AUTOSAR XML (schema 00048)
package /AUTOLIV/SoftwareComponents/CIL
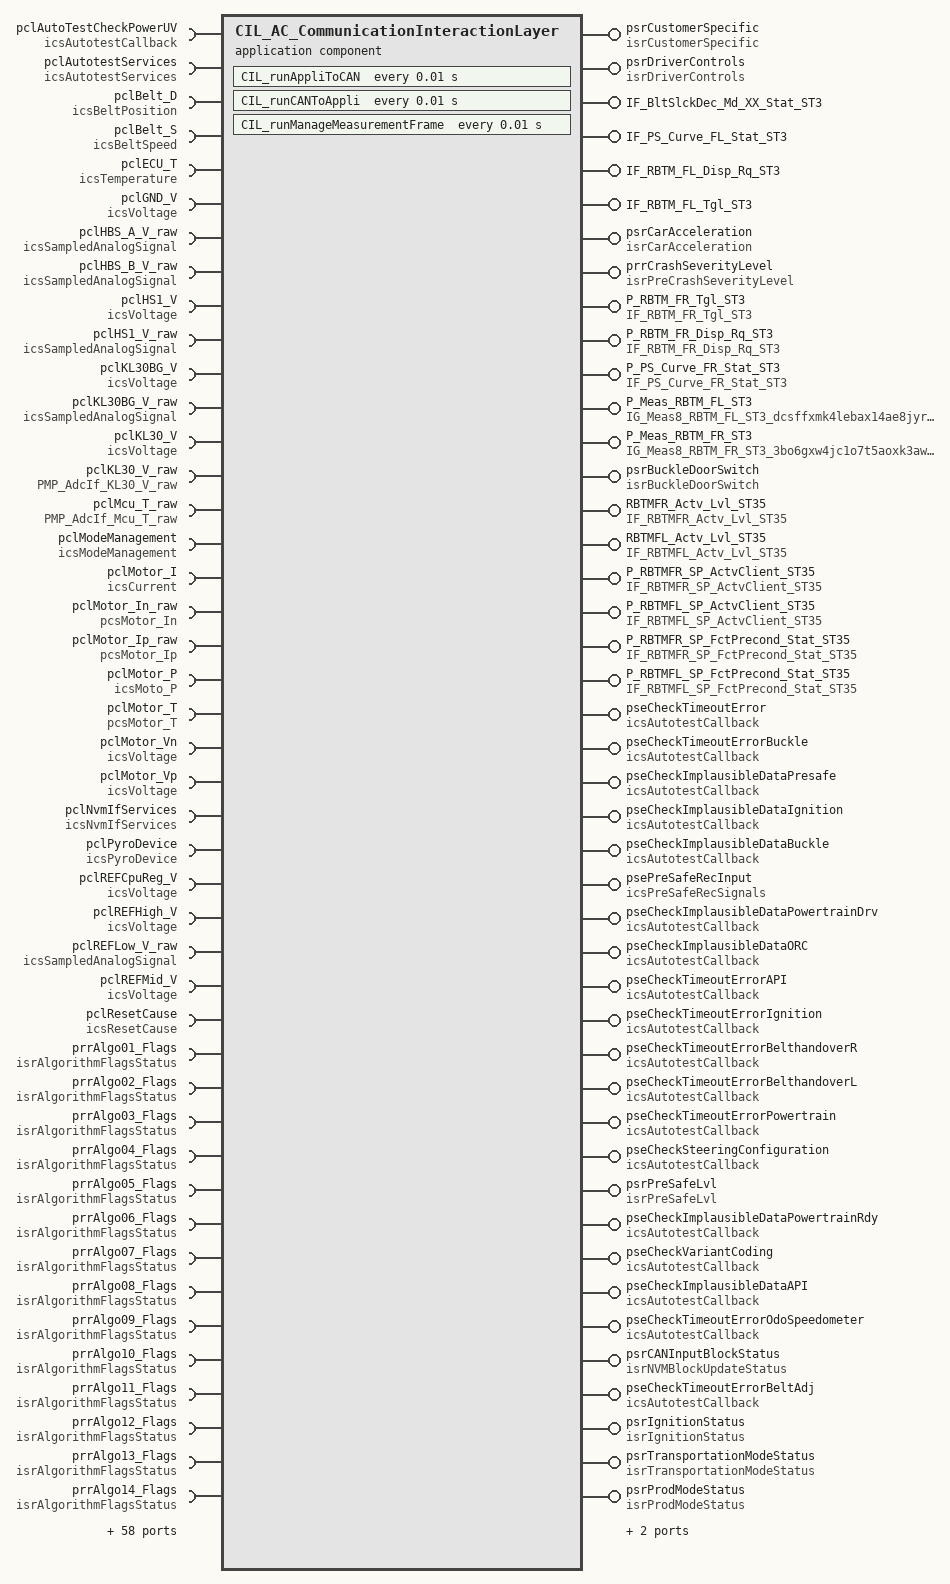
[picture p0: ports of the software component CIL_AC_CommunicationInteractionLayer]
  application sw component type CIL_AC_CommunicationInteractionLayer
    69 x require port:
      pclAutoTestCheckPowerUV: client-com-spec=AutotestCallback, required-interface=icsAutotestCallback
      pclAutotestServices: required-com-specs=[GetLastCriticalAutotestID, GetTestResult], required-interface=icsAutotestServices
      pclBelt_D: required-com-specs=[GetFromMinPos_deg, GetFromMinPos_mm, GetFromT0_deg, GetFromT0_mm, GetRange_deg, GetRange_mm], required-interface=icsBeltPosition
      pclBelt_S: required-com-specs=[GetSpeed_SingleEdge_deg_s, GetSpeed_deg_s, GetSpeed_mm_s], required-interface=icsBeltSpeed
      pclECU_T: required-com-specs=[GetFiltered, GetFiltered_deg, Init], required-interface=icsTemperature
      pclGND_V: required-com-specs=[Get, Get_100ms, Get_10ms, Get_20ms, Get_2ms], required-interface=icsVoltage
      pclHBS_A_V_raw: required-com-specs=[Get, Get_100ms, Get_10ms, Get_20ms, Get_2ms], required-interface=icsSampledAnalogSignal
      pclHBS_B_V_raw: required-com-specs=[Get, Get_100ms, Get_10ms, Get_20ms, Get_2ms], required-interface=icsSampledAnalogSignal
      pclHS1_V: required-com-specs=[Get, Get_100ms, Get_10ms, Get_20ms, Get_2ms], required-interface=icsVoltage
      pclHS1_V_raw: required-com-specs=[Get, Get_100ms, Get_10ms, Get_20ms, Get_2ms], required-interface=icsSampledAnalogSignal
      pclKL30BG_V: required-com-specs=[Get, Get_100ms, Get_10ms, Get_20ms, Get_2ms], required-interface=icsVoltage
      pclKL30BG_V_raw: required-com-specs=[Get, Get_100ms, Get_10ms, Get_20ms, Get_2ms], required-interface=icsSampledAnalogSignal
      pclKL30_V: required-com-specs=[Get, Get_100ms, Get_10ms, Get_20ms, Get_2ms], required-interface=icsVoltage
      pclKL30_V_raw: required-com-specs=[Get_10ms, Get_100ms, Get, Get_20ms, Get_2ms], required-interface=PMP_AdcIf_KL30_V_raw
      pclMcu_T_raw: client-com-spec=Get_10ms, required-interface=PMP_AdcIf_Mcu_T_raw
      pclModeManagement: client-com-spec=CheckModeStatus, required-interface=icsModeManagement
      pclMotor_I: required-com-specs=[ConvertCurrent_mAtoLSB, Get_A, Get_LSB, Get_mA], required-interface=icsCurrent
      pclMotor_In_raw: required-com-specs=[raw_Get_10ms, raw_Get], required-interface=pcsMotor_In
      pclMotor_Ip_raw: required-com-specs=[raw_Get_10ms, raw_Get], required-interface=pcsMotor_Ip
      pclMotor_P: required-com-specs=[GetPowerOrder, SetPowerOrder], required-interface=icsMoto_P
      pclMotor_T: required-com-specs=[GetDeficiencyLevel, InitializeDeficiencyLevel], required-interface=pcsMotor_T
      pclMotor_Vn: required-com-specs=[Get, Get_100ms, Get_10ms, Get_20ms, Get_2ms], required-interface=icsVoltage
      pclMotor_Vp: required-com-specs=[Get, Get_100ms, Get_10ms, Get_20ms, Get_2ms], required-interface=icsVoltage
      pclNvmIfServices: required-com-specs=[GetCalibBlockLength, GetNvmBlockLength, GetNvmBlockStatus, SynchronousRecord], required-interface=icsNvmIfServices
      pclPyroDevice: client-com-spec=GetPyroActivationStatus, required-interface=icsPyroDevice
      pclREFCpuReg_V: required-com-specs=[Get, Get_100ms, Get_10ms, Get_20ms, Get_2ms], required-interface=icsVoltage
      pclREFHigh_V: required-com-specs=[Get, Get_100ms, Get_10ms, Get_20ms, Get_2ms], required-interface=icsVoltage
      pclREFLow_V_raw: required-com-specs=[Get, Get_100ms, Get_10ms, Get_20ms, Get_2ms], required-interface=icsSampledAnalogSignal
      pclREFMid_V: required-com-specs=[Get, Get_100ms, Get_10ms, Get_20ms, Get_2ms], required-interface=icsVoltage
      pclResetCause: required-com-specs=[ConfirmResetCause, DetermineResetCause, GetResetCause], required-interface=icsResetCause
      prrAlgo01_Flags: required-interface=isrAlgorithmFlagsStatus
        required-com-specs:
          data-element=b8InterruptFlag, init-value=constant-reference=APPLINIT_KB8_ALGO_FLAG_FALSE
          data-element=b8PreActivationFlag, init-value=constant-reference=APPLINIT_KB8_ALGO_FLAG_FALSE
          data-element=b8PreConditionsFlag, init-value=constant-reference=APPLINIT_KB8_ALGO_FLAG_FALSE
          data-element=b8TriggerFlag, init-value=constant-reference=APPLINIT_KB8_ALGO_FLAG_FALSE
          data-element=u8TriggeringSource, init-value=constant-reference=APPLINIT_KU8_TRIGGERING_SOURCE_NO
      prrAlgo02_Flags: required-interface=isrAlgorithmFlagsStatus
        required-com-specs:
          data-element=b8InterruptFlag, init-value=constant-reference=APPLINIT_KB8_ALGO_FLAG_FALSE
          data-element=b8PreActivationFlag, init-value=constant-reference=APPLINIT_KB8_ALGO_FLAG_FALSE
          data-element=b8PreConditionsFlag, init-value=constant-reference=APPLINIT_KB8_ALGO_FLAG_FALSE
          data-element=b8TriggerFlag, init-value=constant-reference=APPLINIT_KB8_ALGO_FLAG_FALSE
          data-element=u8TriggeringSource, init-value=constant-reference=APPLINIT_KU8_TRIGGERING_SOURCE_NO
      prrAlgo03_Flags: required-interface=isrAlgorithmFlagsStatus
        required-com-specs:
          data-element=b8InterruptFlag, init-value=constant-reference=APPLINIT_KB8_ALGO_FLAG_FALSE
          data-element=b8PreActivationFlag, init-value=constant-reference=APPLINIT_KB8_ALGO_FLAG_FALSE
          data-element=b8PreConditionsFlag, init-value=constant-reference=APPLINIT_KB8_ALGO_FLAG_FALSE
          data-element=b8TriggerFlag, init-value=constant-reference=APPLINIT_KB8_ALGO_FLAG_FALSE
          data-element=u8TriggeringSource, init-value=constant-reference=APPLINIT_KU8_TRIGGERING_SOURCE_NO
      prrAlgo04_Flags: required-interface=isrAlgorithmFlagsStatus
        required-com-specs:
          data-element=b8InterruptFlag, init-value=constant-reference=APPLINIT_KB8_ALGO_FLAG_FALSE
          data-element=b8PreActivationFlag, init-value=constant-reference=APPLINIT_KB8_ALGO_FLAG_FALSE
          data-element=b8PreConditionsFlag, init-value=constant-reference=APPLINIT_KB8_ALGO_FLAG_FALSE
          data-element=b8TriggerFlag, init-value=constant-reference=APPLINIT_KB8_ALGO_FLAG_FALSE
          data-element=u8TriggeringSource, init-value=constant-reference=APPLINIT_KU8_TRIGGERING_SOURCE_NO
      prrAlgo05_Flags: required-interface=isrAlgorithmFlagsStatus
        required-com-specs:
          data-element=b8InterruptFlag, init-value=constant-reference=APPLINIT_KB8_ALGO_FLAG_FALSE
          data-element=b8PreActivationFlag, init-value=constant-reference=APPLINIT_KB8_ALGO_FLAG_FALSE
          data-element=b8PreConditionsFlag, init-value=constant-reference=APPLINIT_KB8_ALGO_FLAG_FALSE
          data-element=b8TriggerFlag, init-value=constant-reference=APPLINIT_KB8_ALGO_FLAG_FALSE
          data-element=u8TriggeringSource, init-value=constant-reference=APPLINIT_KU8_TRIGGERING_SOURCE_NO
      prrAlgo06_Flags: required-interface=isrAlgorithmFlagsStatus
        required-com-specs:
          data-element=b8InterruptFlag, init-value=constant-reference=APPLINIT_KB8_ALGO_FLAG_FALSE
          data-element=b8PreActivationFlag, init-value=constant-reference=APPLINIT_KB8_ALGO_FLAG_FALSE
          data-element=b8PreConditionsFlag, init-value=constant-reference=APPLINIT_KB8_ALGO_FLAG_FALSE
          data-element=b8TriggerFlag, init-value=constant-reference=APPLINIT_KB8_ALGO_FLAG_FALSE
          data-element=u8TriggeringSource, init-value=constant-reference=APPLINIT_KU8_TRIGGERING_SOURCE_NO
      prrAlgo07_Flags: required-interface=isrAlgorithmFlagsStatus
        required-com-specs:
          data-element=b8InterruptFlag, init-value=constant-reference=APPLINIT_KB8_ALGO_FLAG_FALSE
          data-element=b8PreActivationFlag, init-value=constant-reference=APPLINIT_KB8_ALGO_FLAG_FALSE
          data-element=b8PreConditionsFlag, init-value=constant-reference=APPLINIT_KB8_ALGO_FLAG_FALSE
          data-element=b8TriggerFlag, init-value=constant-reference=APPLINIT_KB8_ALGO_FLAG_FALSE
          data-element=u8TriggeringSource, init-value=constant-reference=APPLINIT_KU8_TRIGGERING_SOURCE_NO
      prrAlgo08_Flags: required-interface=isrAlgorithmFlagsStatus
        required-com-specs:
          data-element=b8InterruptFlag, init-value=constant-reference=APPLINIT_KB8_ALGO_FLAG_FALSE
          data-element=b8PreActivationFlag, init-value=constant-reference=APPLINIT_KB8_ALGO_FLAG_FALSE
          data-element=b8PreConditionsFlag, init-value=constant-reference=APPLINIT_KB8_ALGO_FLAG_FALSE
          data-element=b8TriggerFlag, init-value=constant-reference=APPLINIT_KB8_ALGO_FLAG_FALSE
          data-element=u8TriggeringSource, init-value=constant-reference=APPLINIT_KU8_TRIGGERING_SOURCE_NO
      prrAlgo09_Flags: required-interface=isrAlgorithmFlagsStatus
        required-com-specs:
          data-element=b8InterruptFlag, init-value=constant-reference=APPLINIT_KB8_ALGO_FLAG_FALSE
          data-element=b8PreActivationFlag, init-value=constant-reference=APPLINIT_KB8_ALGO_FLAG_FALSE
          data-element=b8PreConditionsFlag, init-value=constant-reference=APPLINIT_KB8_ALGO_FLAG_FALSE
          data-element=b8TriggerFlag, init-value=constant-reference=APPLINIT_KB8_ALGO_FLAG_FALSE
          data-element=u8TriggeringSource, init-value=constant-reference=APPLINIT_KU8_TRIGGERING_SOURCE_NO
      prrAlgo10_Flags: required-interface=isrAlgorithmFlagsStatus
        required-com-specs:
          data-element=b8InterruptFlag, init-value=constant-reference=APPLINIT_KB8_ALGO_FLAG_FALSE
          data-element=b8PreActivationFlag, init-value=constant-reference=APPLINIT_KB8_ALGO_FLAG_FALSE
          data-element=b8PreConditionsFlag, init-value=constant-reference=APPLINIT_KB8_ALGO_FLAG_FALSE
          data-element=b8TriggerFlag, init-value=constant-reference=APPLINIT_KB8_ALGO_FLAG_FALSE
          data-element=u8TriggeringSource, init-value=constant-reference=APPLINIT_KU8_TRIGGERING_SOURCE_NO
      prrAlgo11_Flags: required-interface=isrAlgorithmFlagsStatus
        required-com-specs:
          data-element=b8InterruptFlag, init-value=constant-reference=APPLINIT_KB8_ALGO_FLAG_FALSE
          data-element=b8PreActivationFlag, init-value=constant-reference=APPLINIT_KB8_ALGO_FLAG_FALSE
          data-element=b8PreConditionsFlag, init-value=constant-reference=APPLINIT_KB8_ALGO_FLAG_FALSE
          data-element=b8TriggerFlag, init-value=constant-reference=APPLINIT_KB8_ALGO_FLAG_FALSE
          data-element=u8TriggeringSource, init-value=constant-reference=APPLINIT_KU8_TRIGGERING_SOURCE_NO
      prrAlgo12_Flags: required-interface=isrAlgorithmFlagsStatus
        required-com-specs:
          data-element=b8InterruptFlag, init-value=constant-reference=APPLINIT_KB8_ALGO_FLAG_FALSE
          data-element=b8PreActivationFlag, init-value=constant-reference=APPLINIT_KB8_ALGO_FLAG_FALSE
          data-element=b8PreConditionsFlag, init-value=constant-reference=APPLINIT_KB8_ALGO_FLAG_FALSE
          data-element=b8TriggerFlag, init-value=constant-reference=APPLINIT_KB8_ALGO_FLAG_FALSE
          data-element=u8TriggeringSource, init-value=constant-reference=APPLINIT_KU8_TRIGGERING_SOURCE_NO
      prrAlgo13_Flags: required-interface=isrAlgorithmFlagsStatus
        required-com-specs:
          data-element=b8InterruptFlag, init-value=constant-reference=APPLINIT_KB8_ALGO_FLAG_FALSE
          data-element=b8PreActivationFlag, init-value=constant-reference=APPLINIT_KB8_ALGO_FLAG_FALSE
          data-element=b8PreConditionsFlag, init-value=constant-reference=APPLINIT_KB8_ALGO_FLAG_FALSE
          data-element=b8TriggerFlag, init-value=constant-reference=APPLINIT_KB8_ALGO_FLAG_FALSE
          data-element=u8TriggeringSource, init-value=constant-reference=APPLINIT_KU8_TRIGGERING_SOURCE_NO
      prrAlgo14_Flags: required-interface=isrAlgorithmFlagsStatus
        required-com-specs:
          data-element=b8InterruptFlag, init-value=constant-reference=APPLINIT_KB8_ALGO_FLAG_FALSE
          data-element=b8PreActivationFlag, init-value=constant-reference=APPLINIT_KB8_ALGO_FLAG_FALSE
          data-element=b8PreConditionsFlag, init-value=constant-reference=APPLINIT_KB8_ALGO_FLAG_FALSE
          data-element=b8TriggerFlag, init-value=constant-reference=APPLINIT_KB8_ALGO_FLAG_FALSE
          data-element=u8TriggeringSource, init-value=constant-reference=APPLINIT_KU8_TRIGGERING_SOURCE_NO
      prrAlgo15_Flags: required-interface=isrAlgorithmFlagsStatus
        required-com-specs:
          data-element=b8InterruptFlag, init-value=constant-reference=APPLINIT_KB8_ALGO_FLAG_FALSE
          data-element=b8PreActivationFlag, init-value=constant-reference=APPLINIT_KB8_ALGO_FLAG_FALSE
          data-element=b8PreConditionsFlag, init-value=constant-reference=APPLINIT_KB8_ALGO_FLAG_FALSE
          data-element=b8TriggerFlag, init-value=constant-reference=APPLINIT_KB8_ALGO_FLAG_FALSE
          data-element=u8TriggeringSource, init-value=constant-reference=APPLINIT_KU8_TRIGGERING_SOURCE_NO
      prrAlgo16_Flags: required-interface=isrAlgorithmFlagsStatus
        required-com-specs:
          data-element=b8InterruptFlag, init-value=constant-reference=APPLINIT_KB8_ALGO_FLAG_FALSE
          data-element=b8PreActivationFlag, init-value=constant-reference=APPLINIT_KB8_ALGO_FLAG_FALSE
          data-element=b8PreConditionsFlag, init-value=constant-reference=APPLINIT_KB8_ALGO_FLAG_FALSE
          data-element=b8TriggerFlag, init-value=constant-reference=APPLINIT_KB8_ALGO_FLAG_FALSE
          data-element=u8TriggeringSource, init-value=constant-reference=APPLINIT_KU8_TRIGGERING_SOURCE_NO
      prrAlgo17_Flags: required-interface=isrAlgorithmFlagsStatus
        required-com-specs:
          data-element=b8InterruptFlag, init-value=constant-reference=APPLINIT_KB8_ALGO_FLAG_FALSE
          data-element=b8PreActivationFlag, init-value=constant-reference=APPLINIT_KB8_ALGO_FLAG_FALSE
          data-element=b8PreConditionsFlag, init-value=constant-reference=APPLINIT_KB8_ALGO_FLAG_FALSE
          data-element=b8TriggerFlag, init-value=constant-reference=APPLINIT_KB8_ALGO_FLAG_FALSE
          data-element=u8TriggeringSource, init-value=constant-reference=APPLINIT_KU8_TRIGGERING_SOURCE_NO
      prrAlgo18_Flags: required-interface=isrAlgorithmFlagsStatus
        required-com-specs:
          data-element=b8InterruptFlag, init-value=constant-reference=APPLINIT_KB8_ALGO_FLAG_FALSE
          data-element=b8PreActivationFlag, init-value=constant-reference=APPLINIT_KB8_ALGO_FLAG_FALSE
          data-element=b8PreConditionsFlag, init-value=constant-reference=APPLINIT_KB8_ALGO_FLAG_FALSE
          data-element=b8TriggerFlag, init-value=constant-reference=APPLINIT_KB8_ALGO_FLAG_FALSE
          data-element=u8TriggeringSource, init-value=constant-reference=APPLINIT_KU8_TRIGGERING_SOURCE_NO
      prrAlgo19_Flags: required-interface=isrAlgorithmFlagsStatus
        required-com-specs:
          data-element=b8InterruptFlag, init-value=constant-reference=APPLINIT_KB8_ALGO_FLAG_FALSE
          data-element=b8PreActivationFlag, init-value=constant-reference=APPLINIT_KB8_ALGO_FLAG_FALSE
          data-element=b8PreConditionsFlag, init-value=constant-reference=APPLINIT_KB8_ALGO_FLAG_FALSE
          data-element=b8TriggerFlag, init-value=constant-reference=APPLINIT_KB8_ALGO_FLAG_FALSE
          data-element=u8TriggeringSource, init-value=constant-reference=APPLINIT_KU8_TRIGGERING_SOURCE_NO
      prrAlgo20_Flags: required-interface=isrAlgorithmFlagsStatus
        required-com-specs:
          data-element=b8InterruptFlag, init-value=constant-reference=APPLINIT_KB8_ALGO_FLAG_FALSE
          data-element=b8PreActivationFlag, init-value=constant-reference=APPLINIT_KB8_ALGO_FLAG_FALSE
          data-element=b8PreConditionsFlag, init-value=constant-reference=APPLINIT_KB8_ALGO_FLAG_FALSE
          data-element=b8TriggerFlag, init-value=constant-reference=APPLINIT_KB8_ALGO_FLAG_FALSE
          data-element=u8TriggeringSource, init-value=constant-reference=APPLINIT_KU8_TRIGGERING_SOURCE_NO
      prrAlgo21_Flags: required-interface=isrAlgorithmFlagsStatus
        required-com-specs:
          data-element=b8InterruptFlag, init-value=constant-reference=APPLINIT_KB8_ALGO_FLAG_FALSE
          data-element=b8PreActivationFlag, init-value=constant-reference=APPLINIT_KB8_ALGO_FLAG_FALSE
          data-element=b8PreConditionsFlag, init-value=constant-reference=APPLINIT_KB8_ALGO_FLAG_FALSE
          data-element=b8TriggerFlag, init-value=constant-reference=APPLINIT_KB8_ALGO_FLAG_FALSE
          data-element=u8TriggeringSource, init-value=constant-reference=APPLINIT_KU8_TRIGGERING_SOURCE_NO
      prrAlgo22_Flags: required-interface=isrAlgorithmFlagsStatus
        required-com-specs:
          data-element=b8InterruptFlag, init-value=constant-reference=APPLINIT_KB8_ALGO_FLAG_FALSE
          data-element=b8PreActivationFlag, init-value=constant-reference=APPLINIT_KB8_ALGO_FLAG_FALSE
          data-element=b8PreConditionsFlag, init-value=constant-reference=APPLINIT_KB8_ALGO_FLAG_FALSE
          data-element=b8TriggerFlag, init-value=constant-reference=APPLINIT_KB8_ALGO_FLAG_FALSE
          data-element=u8TriggeringSource, init-value=constant-reference=APPLINIT_KU8_TRIGGERING_SOURCE_NO
      prrAlgo23_Flags: required-interface=isrAlgorithmFlagsStatus
        required-com-specs:
          data-element=b8InterruptFlag, init-value=constant-reference=APPLINIT_KB8_ALGO_FLAG_FALSE
          data-element=b8PreActivationFlag, init-value=constant-reference=APPLINIT_KB8_ALGO_FLAG_FALSE
          data-element=b8PreConditionsFlag, init-value=constant-reference=APPLINIT_KB8_ALGO_FLAG_FALSE
          data-element=b8TriggerFlag, init-value=constant-reference=APPLINIT_KB8_ALGO_FLAG_FALSE
          data-element=u8TriggeringSource, init-value=constant-reference=APPLINIT_KU8_TRIGGERING_SOURCE_NO
      prrAlgo24_Flags: required-interface=isrAlgorithmFlagsStatus
        required-com-specs:
          data-element=b8InterruptFlag, init-value=constant-reference=APPLINIT_KB8_ALGO_FLAG_FALSE
          data-element=b8PreActivationFlag, init-value=constant-reference=APPLINIT_KB8_ALGO_FLAG_FALSE
          data-element=b8PreConditionsFlag, init-value=constant-reference=APPLINIT_KB8_ALGO_FLAG_FALSE
          data-element=b8TriggerFlag, init-value=constant-reference=APPLINIT_KB8_ALGO_FLAG_FALSE
          data-element=u8TriggeringSource, init-value=constant-reference=APPLINIT_KU8_TRIGGERING_SOURCE_NO
      prrAlgo25_Flags: required-interface=isrAlgorithmFlagsStatus
        required-com-specs:
          data-element=b8InterruptFlag, init-value=constant-reference=APPLINIT_KB8_ALGO_FLAG_FALSE
          data-element=b8PreActivationFlag, init-value=constant-reference=APPLINIT_KB8_ALGO_FLAG_FALSE
          data-element=b8PreConditionsFlag, init-value=constant-reference=APPLINIT_KB8_ALGO_FLAG_FALSE
          data-element=b8TriggerFlag, init-value=constant-reference=APPLINIT_KB8_ALGO_FLAG_FALSE
          data-element=u8TriggeringSource, init-value=constant-reference=APPLINIT_KU8_TRIGGERING_SOURCE_NO
      prrAlgo26_Flags: required-interface=isrAlgorithmFlagsStatus
        required-com-specs:
          data-element=b8InterruptFlag, init-value=constant-reference=APPLINIT_KB8_ALGO_FLAG_FALSE
          data-element=b8PreActivationFlag, init-value=constant-reference=APPLINIT_KB8_ALGO_FLAG_FALSE
          data-element=b8PreConditionsFlag, init-value=constant-reference=APPLINIT_KB8_ALGO_FLAG_FALSE
          data-element=b8TriggerFlag, init-value=constant-reference=APPLINIT_KB8_ALGO_FLAG_FALSE
          data-element=u8TriggeringSource, init-value=constant-reference=APPLINIT_KU8_TRIGGERING_SOURCE_NO
      prrAlgo30_Flags: required-interface=isrAlgorithmFlagsStatus
        required-com-specs:
          data-element=b8InterruptFlag, init-value=constant-reference=APPLINIT_KB8_ALGO_FLAG_FALSE
          data-element=b8PreActivationFlag, init-value=constant-reference=APPLINIT_KB8_ALGO_FLAG_FALSE
          data-element=b8PreConditionsFlag, init-value=constant-reference=APPLINIT_KB8_ALGO_FLAG_FALSE
          data-element=b8TriggerFlag, init-value=constant-reference=APPLINIT_KB8_ALGO_FLAG_FALSE
          data-element=u8TriggeringSource, init-value=constant-reference=APPLINIT_KU8_TRIGGERING_SOURCE_NO
      prrAlgo31_Flags: required-interface=isrAlgorithmFlagsStatus
        required-com-specs:
          data-element=b8InterruptFlag, init-value=constant-reference=APPLINIT_KB8_ALGO_FLAG_FALSE
          data-element=b8PreActivationFlag, init-value=constant-reference=APPLINIT_KB8_ALGO_FLAG_FALSE
          data-element=b8PreConditionsFlag, init-value=constant-reference=APPLINIT_KB8_ALGO_FLAG_FALSE
          data-element=b8TriggerFlag, init-value=constant-reference=APPLINIT_KB8_ALGO_FLAG_FALSE
          data-element=u8TriggeringSource, init-value=constant-reference=APPLINIT_KU8_TRIGGERING_SOURCE_NO
      prrAlgo32_Flags: required-interface=isrAlgorithmFlagsStatus
        required-com-specs:
          data-element=b8InterruptFlag, init-value=constant-reference=APPLINIT_KB8_ALGO_FLAG_FALSE
          data-element=b8PreActivationFlag, init-value=constant-reference=APPLINIT_KB8_ALGO_FLAG_FALSE
          data-element=b8PreConditionsFlag, init-value=constant-reference=APPLINIT_KB8_ALGO_FLAG_FALSE
          data-element=b8TriggerFlag, init-value=constant-reference=APPLINIT_KB8_ALGO_FLAG_FALSE
          data-element=u8TriggeringSource, init-value=constant-reference=APPLINIT_KU8_TRIGGERING_SOURCE_NO
      prrAlgo33_Flags: required-interface=isrAlgorithmFlagsStatus
        required-com-specs:
          data-element=b8InterruptFlag, init-value=constant-reference=APPLINIT_KB8_ALGO_FLAG_FALSE
          data-element=b8PreActivationFlag, init-value=constant-reference=APPLINIT_KB8_ALGO_FLAG_FALSE
          data-element=b8PreConditionsFlag, init-value=constant-reference=APPLINIT_KB8_ALGO_FLAG_FALSE
          data-element=b8TriggerFlag, init-value=constant-reference=APPLINIT_KB8_ALGO_FLAG_FALSE
          data-element=u8TriggeringSource, init-value=constant-reference=APPLINIT_KU8_TRIGGERING_SOURCE_NO
      prrAlgo34_Flags: required-interface=isrAlgorithmFlagsStatus
        required-com-specs:
          data-element=b8InterruptFlag, init-value=constant-reference=APPLINIT_KB8_ALGO_FLAG_FALSE
          data-element=b8PreActivationFlag, init-value=constant-reference=APPLINIT_KB8_ALGO_FLAG_FALSE
          data-element=b8PreConditionsFlag, init-value=constant-reference=APPLINIT_KB8_ALGO_FLAG_FALSE
          data-element=b8TriggerFlag, init-value=constant-reference=APPLINIT_KB8_ALGO_FLAG_FALSE
          data-element=u8TriggeringSource, init-value=constant-reference=APPLINIT_KU8_TRIGGERING_SOURCE_NO
      prrAlgo35_Flags: required-interface=isrAlgorithmFlagsStatus
        required-com-specs:
          data-element=b8InterruptFlag, init-value=constant-reference=APPLINIT_KB8_ALGO_FLAG_FALSE
          data-element=b8PreActivationFlag, init-value=constant-reference=APPLINIT_KB8_ALGO_FLAG_FALSE
          data-element=b8PreConditionsFlag, init-value=constant-reference=APPLINIT_KB8_ALGO_FLAG_FALSE
          data-element=b8TriggerFlag, init-value=constant-reference=APPLINIT_KB8_ALGO_FLAG_FALSE
          data-element=u8TriggeringSource, init-value=constant-reference=APPLINIT_KU8_TRIGGERING_SOURCE_NO
      prrAlgo36_Flags: required-interface=isrAlgorithmFlagsStatus
        required-com-specs:
          data-element=b8InterruptFlag, init-value=constant-reference=APPLINIT_KB8_ALGO_FLAG_FALSE
          data-element=b8PreActivationFlag, init-value=constant-reference=APPLINIT_KB8_ALGO_FLAG_FALSE
          data-element=b8PreConditionsFlag, init-value=constant-reference=APPLINIT_KB8_ALGO_FLAG_FALSE
          data-element=b8TriggerFlag, init-value=constant-reference=APPLINIT_KB8_ALGO_FLAG_FALSE
          data-element=u8TriggeringSource, init-value=constant-reference=APPLINIT_KU8_TRIGGERING_SOURCE_NO
      prrAlgo37_Flags: required-interface=isrAlgorithmFlagsStatus
        required-com-specs:
          data-element=b8InterruptFlag, init-value=constant-reference=APPLINIT_KB8_ALGO_FLAG_FALSE
          data-element=b8PreActivationFlag, init-value=constant-reference=APPLINIT_KB8_ALGO_FLAG_FALSE
          data-element=b8PreConditionsFlag, init-value=constant-reference=APPLINIT_KB8_ALGO_FLAG_FALSE
          data-element=b8TriggerFlag, init-value=constant-reference=APPLINIT_KB8_ALGO_FLAG_FALSE
          data-element=u8TriggeringSource, init-value=constant-reference=APPLINIT_KU8_TRIGGERING_SOURCE_NO
      prrAlgo38_Flags: required-interface=isrAlgorithmFlagsStatus
        required-com-specs:
          data-element=b8InterruptFlag, init-value=constant-reference=APPLINIT_KB8_ALGO_FLAG_FALSE
          data-element=b8PreActivationFlag, init-value=constant-reference=APPLINIT_KB8_ALGO_FLAG_FALSE
          data-element=b8PreConditionsFlag, init-value=constant-reference=APPLINIT_KB8_ALGO_FLAG_FALSE
          data-element=b8TriggerFlag, init-value=constant-reference=APPLINIT_KB8_ALGO_FLAG_FALSE
          data-element=u8TriggeringSource, init-value=constant-reference=APPLINIT_KU8_TRIGGERING_SOURCE_NO
      prrBeltStackAntipatina: nonqueued-receiver-com-spec{data-element=b8BeltStack, init-value=0}, required-interface=isrBeltStack
      prrCycleNumber: nonqueued-receiver-com-spec{data-element=u8CycleNumber, init-value=constant-reference=APPLINIT_KU8_CYCLE_NUMBER_NONE}, required-interface=isrCycleNumber
      prrSelectedCycle: nonqueued-receiver-com-spec{data-element=u8CycleNumber, init-value=constant-reference=APPLINIT_KU8_CYCLE_NUMBER_NONE}, required-interface=isrCycleNumber
      prrStepNumber: nonqueued-receiver-com-spec{data-element=u8StepNumber, init-value=constant-reference=APPLINIT_KU8_STEP_NUMBER_NONE}, required-interface=isrStepNumber
    6 x provide port:
      psrCustomerSpecific: provided-interface=isrCustomerSpecific
        provided-com-specs:
          data-element=b8HardReleaseRequest, init-value=constant-reference=APPLINIT_KB8_BOOLEAN_FALSE
          data-element=b8IsCarCrankingActive, init-value=constant-reference=APPLINIT_KB8_CAR_CRANKING_ACTIVE_TRUE
          data-element=b8IsCarCrashDetected, init-value=constant-reference=APPLINIT_KB8_CAR_CRASH_DETECTED_FALSE
          data-element=b8IsTrigOffEventAllowed, init-value=constant-reference=APPLINIT_KB8_BOOLEAN_FALSE
          data-element=b8PreCrashRequestEnable, init-value=constant-reference=APPLINIT_KB8_BOOLEAN_FALSE
          data-element=u8BeltSlackStatus, init-value=constant-reference=APPLINIT_KU8_BELT_SLACK_STATUS_NOT_DEFINED
          data-element=u8HapticRequest, init-value=constant-reference=APPLINIT_KU8_HAPTIC_REQUEST_NO
          data-element=u8PreCrashRequest, init-value=constant-reference=APPLINIT_KU8_PRE_CRASH_REQUEST_NO_REQUEST
          data-element=u8TriggerRequest, init-value=constant-reference=APPLINIT_KU8_CYCLE_NUMBER_NONE
          data-element=b8SignalRelInhibition, init-value=constant-reference=APPLINIT_KB8_BOOLEAN_FALSE
      psrDriverControls: provided-interface=isrDriverControls
        provided-com-specs:
          data-element=b8VehicleMovingBackwards, init-value=constant-reference=APPLINIT_KB8_BOOLEAN_FALSE
          data-element=s16AccelerationPedalPositionRate, init-value=constant-reference=APPLINIT_KS16_ACCEL_PEDAL_POS_RATE_ZERO
          data-element=s16BrakePressureRate, init-value=constant-reference=APPLINIT_KS16_BRAKE_PRESSURE_RATE_ZERO
          data-element=s16HWAngle, init-value=constant-reference=APPLINIT_KS16_HW_ANGLE_ZERO
          data-element=s16HWRate, init-value=constant-reference=APPLINIT_KS16_HW_RATE_ZERO
          data-element=u16BrakePressure, init-value=constant-reference=APPLINIT_KU16_BRAKE_PRESSURE_ZERO
          data-element=u16VehicleSpeed, init-value=constant-reference=APPLINIT_KU16_VEHICLE_SPEED_ZERO
          data-element=u8AccelerationPedalPosition, init-value=constant-reference=APPLINIT_KU8_ACCEL_PEDAL_POS_ZERO
          data-element=u8KlemmenStatus, init-value=constant-reference=APPLINIT_KU8_KLEMMEN_STATUS_ZERO
      IF_BltSlckDec_Md_XX_Stat_ST3: nonqueued-sender-com-spec{data-element=BltSlckDec_Md_XX_Stat_ST3, init-value=constant-reference=XDIS_e0p8eo65xegbkeoit2yb8bj0v}, provided-interface=IF_BltSlckDec_Md_XX_Stat_ST3
      IF_PS_Curve_FL_Stat_ST3: nonqueued-sender-com-spec{data-element=PS_Curve_FL_Stat_ST3, init-value=constant-reference=XDIS_7s3506puhms1tg6jklvb6yyln}, provided-interface=IF_PS_Curve_FL_Stat_ST3
      IF_RBTM_FL_Disp_Rq_ST3: nonqueued-sender-com-spec{data-element=RBTM_FL_Disp_Rq_ST3, init-value=constant-reference=XDIS_mplw7kqzq1h511zsujiz4bgo}, provided-interface=IF_RBTM_FL_Disp_Rq_ST3
      IF_RBTM_FL_Tgl_ST3: nonqueued-sender-com-spec{data-element=RBTM_FL_Tgl_ST3, init-value=constant-reference=XDIS_h5tcyk98kzbgrc5svasomeyt}, provided-interface=IF_RBTM_FL_Tgl_ST3
    4 x require port:
      IG_Ign_Stat_Pr5_ST3: nonqueued-receiver-com-spec{data-element=Ign_Stat_Pr5_ST3, filter=data-filter-type=ALWAYS}, required-interface=IG_Ign_Stat_Pr5_ST3
      IG_ORC_Impact2_Pr5_ST3: nonqueued-receiver-com-spec{data-element=ORC_Impact2_Pr5_ST3, end-to-end-transformation-com-spec-props=disable-end-to-end-check=true, filter=data-filter-type=ALWAYS, init-value=constant-reference=XDIS_6l5b88fcuqpu2imoz1fzls07a}, required-interface=IG_ORC_Impact2_Pr5_ST3_9ccpksmbwqz15ty9t9jr7ps1e  # ORC Impact 2 ST3 (degraded)
      IG_ORC_Impact3_Pr5_ST3: nonqueued-receiver-com-spec{data-element=ORC_Impact3_Pr5_ST3, end-to-end-transformation-com-spec-props=disable-end-to-end-check=false, filter=data-filter-type=ALWAYS, init-value=constant-reference=XDIS_7frhrem3wt9j2oidbosrki6rx}, required-interface=IG_ORC_Impact3_Pr5_ST3_35qgq57bw73eamvx4gelk7iiv
      IG_PresfAct_Adj_Pr5_ST3: nonqueued-receiver-com-spec{data-element=PresfAct_Adj_Pr5_ST3, end-to-end-transformation-com-spec-props=disable-end-to-end-check=false, filter=data-filter-type=ALWAYS, init-value=constant-reference=XDIS_dw79s45ha1z03s9jiw4xye2p4}, required-interface=IG_PresfAct_Adj_Pr5_ST3_863uuptg5wch3t7i31c8crpa2
    5 x provide port:
      psrCarAcceleration: nonqueued-sender-com-spec{data-element=b8IsCarAccelerationLow, uses-end-to-end-protection=true, init-value=constant-reference=APPLINIT_KB8_CAR_ACCEL_LOW_TRUE}, provided-interface=isrCarAcceleration
      prrCrashSeverityLevel: nonqueued-sender-com-spec=u8PreCrashSeverityLevel, provided-interface=isrPreCrashSeverityLevel
      P_RBTM_FR_Tgl_ST3: nonqueued-sender-com-spec{data-element=RBTM_FR_Tgl_ST3, init-value=constant-reference=XDIS_h5tcyk98kzbgrc5svasomeyt}, provided-interface=IF_RBTM_FR_Tgl_ST3  # Presafe Togglebit
      P_RBTM_FR_Disp_Rq_ST3: nonqueued-sender-com-spec{data-element=RBTM_FR_Disp_Rq_ST3, init-value=constant-reference=XDIS_mplw7kqzq1h511zsujiz4bgo}, provided-interface=IF_RBTM_FR_Disp_Rq_ST3  # Presafe display request front right
      P_PS_Curve_FR_Stat_ST3: nonqueued-sender-com-spec{data-element=PS_Curve_FR_Stat_ST3, init-value=constant-reference=XDIS_7s3506puhms1tg6jklvb6yyln}, provided-interface=IF_PS_Curve_FR_Stat_ST3  # PreSafe Curve mode state front right
    require port prrEnableCycle0: nonqueued-receiver-com-spec{data-element=b8CycleValidity, filter=data-filter-type=ALWAYS, init-value=constant-reference=IMPLINIT_KB8_BOOLEAN_FALSE}, required-interface=isrCycleValidity
    require port prrEnableCycle1: nonqueued-receiver-com-spec{data-element=b8CycleValidity, filter=data-filter-type=ALWAYS, init-value=constant-reference=IMPLINIT_KB8_BOOLEAN_FALSE}, required-interface=isrCycleValidity
    provide port P_Meas_RBTM_FL_ST3: nonqueued-sender-com-spec{data-element=Meas8_RBTM_FL_ST3, init-value=constant-reference=XDIS_ckvw3q385offj9s5jhb6jp6cr}, provided-interface=IG_Meas8_RBTM_FL_ST3_dcsffxmk4lebax14ae8jyr2nd  # Measurement (degraded)
    provide port P_Meas_RBTM_FR_ST3: nonqueued-sender-com-spec{data-element=Meas8_RBTM_FR_ST3, init-value=constant-reference=XDIS_byyw7b3ki3w79jkgp9jr5allr}, provided-interface=IG_Meas8_RBTM_FR_ST3_3bo6gxw4jc1o7t5aoxk3awdcy  # Measurement (degraded)
    provide port psrBuckleDoorSwitch: provided-interface=isrBuckleDoorSwitch
      provided-com-specs:
        data-element=u8DoorSwitch, init-value=constant-reference=APPLINIT_KU8_DOOR_SWITCH_STATUS_NOT_DEFINED
        data-element=u8BuckleSwitch, init-value=constant-reference=APPLINIT_KU8_BUCKLE_SWITCH_STATUS_NOT_DEFINED
    4 x require port:
      pclAecStatus: required-interface=icsAecStatus
        required-com-specs:
          SetAecEvent
          GetNumberOfImplementedAec
          GetAecStatus
          GetAecQualificationCount
          GetAecNvpBlockRecordingStatus
          GetAecGroupsStatus
          GetAecDeskillThrs
      prrEnableCycle2: nonqueued-receiver-com-spec{data-element=b8CycleValidity, filter=data-filter-type=ALWAYS, init-value=constant-reference=IMPLINIT_KB8_BOOLEAN_FALSE}, required-interface=isrCycleValidity
      prrEnableCycle3: nonqueued-receiver-com-spec{data-element=b8CycleValidity, filter=data-filter-type=ALWAYS, init-value=constant-reference=IMPLINIT_KB8_BOOLEAN_FALSE}, required-interface=isrCycleValidity
      R_SBeltTens_SP_Lvl_Pr5_ST3: nonqueued-receiver-com-spec{data-element=SBeltTens_SP_Lvl_Pr5_ST3, end-to-end-transformation-com-spec-props{disable-end-to-end-check=false, max-delta-counter=3, max-error-state-init=0, max-error-state-invalid=0, max-error-state-valid=0, min-ok-state-init=1, min-ok-state-invalid=1, min-ok-state-valid=1, window-size=10}, alive-timeout=2, init-value=constant-reference=XDIS_4wiqeqoz18rz4k73xcp12oii1}, required-interface=IG_SBeltTens_SP_Lvl_Pr5_ST3_aljrkz9re372o0jtum2i5lh8w  # Seat Belt Tensioner SP Lvl ST3 (degraded)
    provide port RBTMFR_Actv_Lvl_ST35: nonqueued-sender-com-spec{data-element=RBTMFR_Actv_Lvl_ST35, init-value=63}, provided-interface=IF_RBTMFR_Actv_Lvl_ST35
    provide port RBTMFL_Actv_Lvl_ST35: nonqueued-sender-com-spec{data-element=RBTMFL_Actv_Lvl_ST35, init-value=63}, provided-interface=IF_RBTMFL_Actv_Lvl_ST35
    require port R_PS_Curve_FR_Rq_HU_ST3: nonqueued-receiver-com-spec{data-element=PS_Curve_FR_Rq_HU_ST3, alive-timeout=10.1, init-value=constant-reference=XDIS_avyye5ls1y4c08a0jv466vs3h}, required-interface=IF_PS_Curve_FR_Rq_HU_ST3  # IF PS Curve front right Request(ed) HU ST3
    require port R_PS_Curve_FL_Rq_HU_ST3: nonqueued-receiver-com-spec{data-element=PS_Curve_FL_Rq_HU_ST3, alive-timeout=10.1, init-value=constant-reference=XDIS_avyye5ls1y4c08a0jv466vs3h}, required-interface=IF_PS_Curve_FL_Rq_HU_ST3  # PreSafe Curve mode request from headunit front left
    4 x provide port:
      P_RBTMFR_SP_ActvClient_ST35: nonqueued-sender-com-spec{data-element=RBTMFR_SP_ActvClient_ST35, init-value=constant-reference=XDIS_ech1daxmjqjqyzrsfliduv3re}, provided-interface=IF_RBTMFR_SP_ActvClient_ST35  # Active seatbelt tensioning request source front right
      P_RBTMFL_SP_ActvClient_ST35: nonqueued-sender-com-spec{data-element=RBTMFL_SP_ActvClient_ST35, init-value=constant-reference=XDIS_ech1daxmjqjqyzrsfliduv3re}, provided-interface=IF_RBTMFL_SP_ActvClient_ST35  # Active seatbelt tensioning request source front left
      P_RBTMFR_SP_FctPrecond_Stat_ST35: nonqueued-sender-com-spec{data-element=RBTMFR_SP_FctPrecond_Stat_ST35, init-value=0}, provided-interface=IF_RBTMFR_SP_FctPrecond_Stat_ST35  # List of unfulfilled preconditions for rev. seatbelt tensioning front right
      P_RBTMFL_SP_FctPrecond_Stat_ST35: nonqueued-sender-com-spec{data-element=RBTMFL_SP_FctPrecond_Stat_ST35, init-value=0}, provided-interface=IF_RBTMFL_SP_FctPrecond_Stat_ST35  # List of unfulfilled preconditions for rev. seatbelt tensioning front left
    5 x require port:
      pclDiagRequestCycle: required-com-specs=[ClearDiagRequestCycle, GetDiagRequestCycle], required-interface=icsDiagRequestCycle
      R_Bckl_Sw_Fx_Stat_Pr5_ST3: nonqueued-receiver-com-spec{data-element=Bckl_Sw_Fx_Stat_Pr5_ST3, end-to-end-transformation-com-spec-props{disable-end-to-end-check=false, max-delta-counter=3, max-error-state-init=0, max-error-state-invalid=0, max-error-state-valid=0, min-ok-state-init=1, min-ok-state-invalid=1, min-ok-state-valid=1, window-size=10}, init-value=constant-reference=XDIS_by5k2ulzqy4hav7734lki195k}, required-interface=IG_Bckl_Sw_Fx_Stat_Pr5_ST3_6ckxfn8j26ez9slws8s7zuact  # Bckl Sw Fx state ST3 (degraded)
      prrEnableCycle14: nonqueued-receiver-com-spec{data-element=b8CycleValidity, filter=data-filter-type=ALWAYS, init-value=constant-reference=IMPLINIT_KB8_BOOLEAN_FALSE}, required-interface=isrCycleValidity
      prrEnableCycle18: nonqueued-receiver-com-spec{data-element=b8CycleValidity, filter=data-filter-type=ALWAYS, init-value=constant-reference=IMPLINIT_KB8_BOOLEAN_FALSE}, required-interface=isrCycleValidity
      prrEnableCycle19: nonqueued-receiver-com-spec{data-element=b8CycleValidity, filter=data-filter-type=ALWAYS, init-value=constant-reference=IMPLINIT_KB8_BOOLEAN_FALSE}, required-interface=isrCycleValidity
    5 x provide port, all with server-com-spec{operation=AutotestCallback, queue-length=1}, provided-interface=icsAutotestCallback:
      pseCheckTimeoutError
      pseCheckTimeoutErrorBuckle
      pseCheckImplausibleDataPresafe
      pseCheckImplausibleDataIgnition
      pseCheckImplausibleDataBuckle
    require port prrPresafeDisplay: nonqueued-receiver-com-spec{data-element=b8TriggerPreSafeRequestStatus, filter=data-filter-type=ALWAYS, init-value=constant-reference=APPLINIT_KB8_BOOLEAN_FALSE}, required-interface=isrPresafeDisplay
    9 x provide port:
      psePreSafeRecInput: server-com-spec{operation=GetInputSignals, queue-length=1}, provided-interface=icsPreSafeRecSignals
      pseCheckImplausibleDataPowertrainDrv: server-com-spec{operation=AutotestCallback, queue-length=1}, provided-interface=icsAutotestCallback
      pseCheckImplausibleDataORC: server-com-spec{operation=AutotestCallback, queue-length=1}, provided-interface=icsAutotestCallback
      pseCheckTimeoutErrorAPI: server-com-spec{operation=AutotestCallback, queue-length=1}, provided-interface=icsAutotestCallback
      pseCheckTimeoutErrorIgnition: server-com-spec{operation=AutotestCallback, queue-length=1}, provided-interface=icsAutotestCallback
      pseCheckTimeoutErrorBelthandoverR: server-com-spec{operation=AutotestCallback, queue-length=1}, provided-interface=icsAutotestCallback
      pseCheckTimeoutErrorBelthandoverL: server-com-spec{operation=AutotestCallback, queue-length=1}, provided-interface=icsAutotestCallback
      pseCheckTimeoutErrorPowertrain: server-com-spec{operation=AutotestCallback, queue-length=1}, provided-interface=icsAutotestCallback
      pseCheckSteeringConfiguration: server-com-spec{operation=AutotestCallback, queue-length=1}, provided-interface=icsAutotestCallback
    17 x require port:
      prrEnableCycle{4..7}: nonqueued-receiver-com-spec{data-element=b8CycleValidity, filter=data-filter-type=ALWAYS, init-value=constant-reference=IMPLINIT_KB8_BOOLEAN_FALSE}, required-interface=isrCycleValidity
      prrEnableCycle11: nonqueued-receiver-com-spec{data-element=b8CycleValidity, filter=data-filter-type=ALWAYS, init-value=constant-reference=IMPLINIT_KB8_BOOLEAN_FALSE}, required-interface=isrCycleValidity
      prrEnableCycle{8..10}: nonqueued-receiver-com-spec{data-element=b8CycleValidity, filter=data-filter-type=ALWAYS, init-value=constant-reference=IMPLINIT_KB8_BOOLEAN_FALSE}, required-interface=isrCycleValidity
      prrEnableCycle12: nonqueued-receiver-com-spec{data-element=b8CycleValidity, filter=data-filter-type=ALWAYS, init-value=constant-reference=IMPLINIT_KB8_BOOLEAN_FALSE}, required-interface=isrCycleValidity
      prrEnableCycle13: nonqueued-receiver-com-spec{data-element=b8CycleValidity, filter=data-filter-type=ALWAYS, init-value=constant-reference=IMPLINIT_KB8_BOOLEAN_FALSE}, required-interface=isrCycleValidity
      prrEnableCycle{15..17}: nonqueued-receiver-com-spec{data-element=b8CycleValidity, filter=data-filter-type=ALWAYS, init-value=constant-reference=IMPLINIT_KB8_BOOLEAN_FALSE}, required-interface=isrCycleValidity
      R_BeltHdOvr_XX_Stat_ST3: nonqueued-receiver-com-spec{data-element=BeltHdOvr_XX_Stat_ST3, alive-timeout=5.25, init-value=constant-reference=XDIS_9pu33xhskzhvc3a6idhpuk7uh}, required-interface=IF_BeltHdOvr_XX_Stat_ST3  # Belt hand over state
      R_EVC_CfgList_01_08_Pr5_ST3: nonqueued-receiver-com-spec{data-element=EVC_CfgList_01_08_Pr5_ST3, end-to-end-transformation-com-spec-props=disable-end-to-end-check=true, alive-timeout=2.5, init-value=constant-reference=XDIS_7tqm5jy9oba0thvws62i3l28n}, required-interface=IG_EVC_CfgList_01_08_Pr5_ST3_40zxqtxkwyhasb66rr3qexjf2  # EVC Cfg List 01 08 Pr 5 ST3 (degraded)
      R_PT4_PTCoor4_Pr5_ST3: nonqueued-receiver-com-spec{data-element=PT4_PTCoor4_Pr5_ST3, end-to-end-transformation-com-spec-props=disable-end-to-end-check=true, alive-timeout=1.05, init-value=constant-reference=XDIS_9h6oqehaueepowg2tijus0mir}, required-interface=IG_PT4_PTCoor4_Pr5_ST3_3rxtipq9xm5agzf69e8usehmj  # PT4_PTCoor4_Pr5_ST3 (degraded)
      R_PT4_PTCoor_DrvPosn_Gear_Pr5_ST3: nonqueued-receiver-com-spec{data-element=PT4_PTCoor_DrvPosn_Gear_Pr5_ST3, end-to-end-transformation-com-spec-props=disable-end-to-end-check=true, init-value=constant-reference=XDIS_8ocy3iwo1ditemd6qwphg7b7i}, required-interface=IG_PT4_PTCoor_DrvPosn_Gear_Pr5_ST3_c8lirmw9wm5odas0h648yyd4w  # PT4 PT Coor Drv position Gear Pr 5 ST3 (degraded)
    provide port psrPreSafeLvl: nonqueued-sender-com-spec{data-element=u8PreSafeLvl, init-value=constant-reference=APPLINIT_KU8_PRESAFE_NOLVL}, provided-interface=isrPreSafeLvl
    10 x require port:
      R_BltSlckDec_Md_Rq_HU_ST3: nonqueued-receiver-com-spec{data-element=BltSlckDec_Md_Rq_HU_ST3, alive-timeout=60.5, init-value=constant-reference=XDIS_1vei4uht6zuq0e57z2qtds6y7}, required-interface=IF_BltSlckDec_Md_Rq_HU_ST3  # Anforderung Modus Gurtlosereduktion von Headunit / Belt slack decreasing mode request from Head Unit
      prrEnableCycle{20..28}: nonqueued-receiver-com-spec{data-element=b8CycleValidity, filter=data-filter-type=ALWAYS, init-value=constant-reference=IMPLINIT_KB8_BOOLEAN_FALSE}, required-interface=isrCycleValidity
    7 x provide port:
      pseCheckImplausibleDataPowertrainRdy: server-com-spec{operation=AutotestCallback, queue-length=1}, provided-interface=icsAutotestCallback
      pseCheckVariantCoding: server-com-spec{operation=AutotestCallback, queue-length=1}, provided-interface=icsAutotestCallback
      pseCheckImplausibleDataAPI: server-com-spec{operation=AutotestCallback, queue-length=1}, provided-interface=icsAutotestCallback
      pseCheckTimeoutErrorOdoSpeedometer: server-com-spec{operation=AutotestCallback, queue-length=1}, provided-interface=icsAutotestCallback
      psrCANInputBlockStatus: nonqueued-sender-com-spec=b8NVMBlockStatus, provided-interface=isrNVMBlockUpdateStatus
      pseCheckTimeoutErrorBeltAdj: server-com-spec{operation=AutotestCallback, queue-length=1}, provided-interface=icsAutotestCallback
      psrIgnitionStatus: provided-interface=isrIgnitionStatus
        provided-com-specs:
          data-element=b8TriggerIgnitionStatus, init-value=constant-reference=APPLINIT_KB8_BOOLEAN_FALSE
          data-element=b8TriggerIgnitionStatusEnableStorageCondition, init-value=constant-reference=APPLINIT_KB8_BOOLEAN_FALSE
    require port R_PN14_ProdMd_Stat_ST3: nonqueued-receiver-com-spec{data-element=PN14_ProdMd_Stat_ST3, init-value=constant-reference=XDIS_4um78o9kgep1cp3dhn51ycc2o}, required-interface=IF_PN14_ProdMd_Stat_ST3  # Powernet production mode state
    require port R_PN14_TransMd_Stat_ST3: nonqueued-receiver-com-spec{data-element=PN14_TransMd_Stat_ST3, init-value=constant-reference=XDIS_18rb2bxx4r5d75figzrcw50gp}, required-interface=IF_PN14_TransMd_Stat_ST3  # Powernet transport mode status
    4 x provide port:
      psrTransportationModeStatus: nonqueued-sender-com-spec{data-element=b8TransportationModeStatus, init-value=constant-reference=APPLINIT_KB8_BOOLEAN_TRUE}, provided-interface=isrTransportationModeStatus
      psrProdModeStatus: nonqueued-sender-com-spec{data-element=b8TriggerProdModeStatus, init-value=constant-reference=APPLINIT_KB8_BOOLEAN_TRUE}, provided-interface=isrProdModeStatus
      psrEngStartStatus: nonqueued-sender-com-spec=b8EngStartStatus, provided-interface=isrEngStartStatus
      psrExtTestPres: provided-interface=isrExtTestPres
        provided-com-specs:
          data-element=b8ExtTesterPresent, init-value=constant-reference=APPLINIT_KB8_BOOLEAN_FALSE
          data-element=b8DTCConfirmed, init-value=constant-reference=APPLINIT_KB8_BOOLEAN_FALSE
    require port prrVehicleEquipmentValidity: required-interface=isrVariantCodingValidity
      required-com-specs:
        data-element=u8VehicleEquipValidity, filter=data-filter-type=ALWAYS, init-value=constant-reference=APPLINIT_KB8_BOOLEAN_FALSE
        data-element=u8CodingValidity, filter=data-filter-type=ALWAYS, init-value=constant-reference=APPLINIT_KB8_BOOLEAN_FALSE
    behavior CIL_IB_CommunicationInteractionLayer: data-type-mapping=[DataTypeMappingSet_PP4G, DataTypeMappings_DEV, BswMMappingSet, ComMMode_DataTypeMappingSet, DATA_TYPE_MAPPING_SET, DcmMappingSet, EcuMMode_DataTypeMappingSet, SSATypeMappingSet, WdgMMappingSet]
      timing event CIL_evAppliToCAN: start-on-event=CIL_runAppliToCAN, period=0.01
      timing event CIL_evCANToAppli: start-on-event=CIL_runCANToAppli, period=0.01
      timing event TMT_CIL_runManageMeasurementFrame: start-on-event=CIL_runManageMeasurementFrame, period=0.01
      19 x operation invoked event:
        OIT_CIL_Autotest_Presafe_CheckTimeoutError_pseCheckTimeoutError_AutotestCallback: start-on-event=CIL_Autotest_Presafe_CheckTimeoutError, operation=pseCheckTimeoutError.AutotestCallback
        OIT_CIL_Autotest_BuckleCheckTimeoutError_pse_CheckTimeoutErrorBuckle_AutotestCallback: start-on-event=CIL_Autotest_Buckle_CheckTimeoutError, operation=pseCheckTimeoutErrorBuckle.AutotestCallback
        OIT_CIL_Autotest_CheckImplausibleData_Presafe_pseCheckImplausibleDataPresafe_AutotestCallback: start-on-event=CIL_Autotest_CheckImplausibleData_Presafe, operation=pseCheckImplausibleDataPresafe.AutotestCallback
        OIT_CIL_Autotest_CheckImplausibleData_Ignition_pseCheckImplausibleDataIgnition_AutotestCallback: start-on-event=CIL_Autotest_CheckImplausibleData_Ignition, operation=pseCheckImplausibleDataIgnition.AutotestCallback
        OIT_CIL_Autotest_CheckImplausibleData_Buckle_pseCheckImplausibleDataBuckle_AutotestCallback: start-on-event=CIL_Autotest_CheckImplausibleData_Buckle, operation=pseCheckImplausibleDataBuckle.AutotestCallback
        OIT_CIL_runGetInputSignalPresafeRecorderInfo_psePreSafeRecInput_GetInputSignals: start-on-event=CIL_runGetInputSignalPresafeRecorderInfo, operation=psePreSafeRecInput.GetInputSignals
        OIT_CIL_Autotest_CheckImplausibleData_ORC_pseCheckImplausibleDataORC_AutotestCallback: start-on-event=CIL_Autotest_CheckImplausibleData_ORC, operation=pseCheckImplausibleDataORC.AutotestCallback
        OIT_CIL_Autotest_CheckTimeoutError_API_pseCheckTimeoutErrorAPI_AutotestCallback: start-on-event=CIL_Autotest_CheckTimeoutError_API, operation=pseCheckTimeoutErrorAPI.AutotestCallback
        OIT_CIL_Autotest_CheckTimeoutError_BelthandoverL_pseCheckTimeoutErrorBelthandoverL_AutotestCallback: start-on-event=CIL_Autotest_CheckTimeoutError_BelthandoverL, operation=pseCheckTimeoutErrorBelthandoverL.AutotestCallback
        OIT_CIL_Autotest_CheckTimeoutError_BelthandoverR_pseCheckTimeoutErrorBelthandoverR_AutotestCallback: start-on-event=CIL_Autotest_CheckTimeoutError_BelthandoverR, operation=pseCheckTimeoutErrorBelthandoverR.AutotestCallback
        OIT_CIL_Autotest_CheckTimeoutError_Ignition_pseCheckTimeoutErrorIgnition_AutotestCallback: start-on-event=CIL_Autotest_CheckTimeoutError_Ignition, operation=pseCheckTimeoutErrorIgnition.AutotestCallback
        OIT_CIL_Autotest_CheckTimeoutError_Powertrain_pseCheckTimeoutErrorPowertrain_AutotestCallback: start-on-event=CIL_Autotest_CheckTimeoutError_Powertrain, operation=pseCheckTimeoutErrorPowertrain.AutotestCallback
        OIT_CIL_Autotest_CheckSteeringConfiguration_pseCheckSteeringConfiguration_AutotestCallback: start-on-event=CIL_Autotest_CheckSteeringConfiguration, operation=pseCheckSteeringConfiguration.AutotestCallback
        OIT_CIL_Autotest_CheckImplausibleData_PowertrainDrv_pseCheckImplausibleDataPowertrainDrv_AutotestCallback: start-on-event=CIL_Autotest_CheckImplausibleData_PowertrainDrv, operation=pseCheckImplausibleDataPowertrainDrv.AutotestCallback
        OIT_CIL_Autotest_CheckImplausibleData_PowertrainRdy_pseCheckImplausibleDataPowertrainRdy_AutotestCallback: start-on-event=CIL_Autotest_CheckImplausibleData_PowertrainRdy, operation=pseCheckImplausibleDataPowertrainRdy.AutotestCallback
        OIT_CIL_Autotest_CheckImplausibleData_API_pseCheckImplausibleDataAPI_AutotestCallback: start-on-event=CIL_Autotest_CheckImplausibleData_API, operation=pseCheckImplausibleDataAPI.AutotestCallback
        OIT_CIL_Autotest_CheckVariantCoding_pseCheckVariantCoding_AutotestCallback: start-on-event=CIL_Autotest_CheckVariantCoding, operation=pseCheckVariantCoding.AutotestCallback
        OIT_CIL_Autotest_CheckTimeoutError_OdoSpeedometer_pseCheckTimeoutErrorOdoSpeedometer_AutotestCallback: start-on-event=CIL_Autotest_CheckTimeoutError_OdoSpeedometer, operation=pseCheckTimeoutErrorOdoSpeedometer.AutotestCallback
        OIT_CIL_Autotest_CheckTimeoutError_BeltAdj_pseCheckTimeoutErrorBeltAdj_AutotestCallback: start-on-event=CIL_Autotest_CheckTimeoutError_BeltAdj, operation=pseCheckTimeoutErrorBeltAdj.AutotestCallback
      explicit-inter-runnable-variables:
        6 x data:
          u8BuckleStatus: type=u8lBuckleSwitchStatusType_Appl, init-value=constant-reference=APPLINIT_KU8_BELT_SLACK_STATUS_NOT_DEFINED
          b8CarCrashDetected: type=b8IsCarCrashDetectedType_Appl, init-value=constant-reference=APPLINIT_KB8_CAR_CRASH_DETECTED_FALSE
          b8PreCrashRequestEnable: type=UInt8_Appl, init-value=constant-reference=APPLINIT_KB8_BOOLEAN_FALSE
          u8ActvLvlSignal: type=uint8, init-value=0
          u8FctPrecond_ProfileNotImplemented: type=UInt8, init-value=0
          u8RequestSource: type=uint8, init-value=15
      22 x runnable:
        CIL_runAppliToCAN
          data-receive-point-by-arguments:
            75 x access:
              DRP_prrCycleNumber_u8CycleNumber: accessed-variable=prrCycleNumber.u8CycleNumber
              DRP_prrStepNumber_u8StepNumber: accessed-variable=prrStepNumber.u8StepNumber
              drparg_b8BeltStack: accessed-variable=prrBeltStackAntipatina.b8BeltStack
              drparg_b8PreConditionsFlag: accessed-variable=prrAlgo01_Flags.b8PreConditionsFlag
              drparg_b8PreConditionsFlag1: accessed-variable=prrAlgo02_Flags.b8PreConditionsFlag
              drparg_b8PreConditionsFlag10: accessed-variable=prrAlgo15_Flags.b8PreConditionsFlag
              drparg_b8PreConditionsFlag11: accessed-variable=prrAlgo20_Flags.b8PreConditionsFlag
              drparg_b8PreConditionsFlag12: accessed-variable=prrAlgo21_Flags.b8PreConditionsFlag
              drparg_b8PreConditionsFlag{16..19}: accessed-variable=prrAlgo{16..19}_Flags.b8PreConditionsFlag
              drparg_b8PreConditionsFlag2: accessed-variable=prrAlgo03_Flags.b8PreConditionsFlag
              drparg_b8PreConditionsFlag20: accessed-variable=prrAlgo10_Flags.b8PreConditionsFlag
              drparg_b8PreConditionsFlag21: accessed-variable=prrAlgo11_Flags.b8PreConditionsFlag
              drparg_b8PreConditionsFlag22: accessed-variable=prrAlgo12_Flags.b8PreConditionsFlag
              drparg_b8PreConditionsFlag23: accessed-variable=prrAlgo13_Flags.b8PreConditionsFlag
              drparg_b8PreConditionsFlag24: accessed-variable=prrAlgo22_Flags.b8PreConditionsFlag
              drparg_b8PreConditionsFlag25: accessed-variable=prrAlgo23_Flags.b8PreConditionsFlag
              drparg_b8PreConditionsFlag26: accessed-variable=prrAlgo24_Flags.b8PreConditionsFlag
              drparg_b8PreConditionsFlag27: accessed-variable=prrAlgo25_Flags.b8PreConditionsFlag
              drparg_b8PreConditionsFlag28: accessed-variable=prrAlgo26_Flags.b8PreConditionsFlag
              drparg_b8PreConditionsFlag29: accessed-variable=prrAlgo30_Flags.b8PreConditionsFlag
              drparg_b8PreConditionsFlag3: accessed-variable=prrAlgo04_Flags.b8PreConditionsFlag
              drparg_b8PreConditionsFlag30: accessed-variable=prrAlgo31_Flags.b8PreConditionsFlag
              drparg_b8PreConditionsFlag31: accessed-variable=prrAlgo32_Flags.b8PreConditionsFlag
              drparg_b8PreConditionsFlag32: accessed-variable=prrAlgo33_Flags.b8PreConditionsFlag
              drparg_b8PreConditionsFlag33: accessed-variable=prrAlgo34_Flags.b8PreConditionsFlag
              drparg_b8PreConditionsFlag34: accessed-variable=prrAlgo35_Flags.b8PreConditionsFlag
              drparg_b8PreConditionsFlag35: accessed-variable=prrAlgo36_Flags.b8PreConditionsFlag
              drparg_b8PreConditionsFlag36: accessed-variable=prrAlgo37_Flags.b8PreConditionsFlag
              drparg_b8PreConditionsFlag37: accessed-variable=prrAlgo38_Flags.b8PreConditionsFlag
              drparg_b8PreConditionsFlag4: accessed-variable=prrAlgo05_Flags.b8PreConditionsFlag
              drparg_b8PreConditionsFlag5: accessed-variable=prrAlgo06_Flags.b8PreConditionsFlag
              drparg_b8PreConditionsFlag6: accessed-variable=prrAlgo07_Flags.b8PreConditionsFlag
              drparg_b8PreConditionsFlag7: accessed-variable=prrAlgo08_Flags.b8PreConditionsFlag
              drparg_b8PreConditionsFlag8: accessed-variable=prrAlgo09_Flags.b8PreConditionsFlag
              drparg_b8PreConditionsFlag9: accessed-variable=prrAlgo14_Flags.b8PreConditionsFlag
              drparg_u8TriggeringSource10: accessed-variable=prrAlgo06_Flags.u8TriggeringSource
              drparg_u8TriggeringSource11: accessed-variable=prrAlgo07_Flags.u8TriggeringSource
              drparg_u8TriggeringSource12: accessed-variable=prrAlgo08_Flags.u8TriggeringSource
              drparg_u8TriggeringSource13: accessed-variable=prrAlgo09_Flags.u8TriggeringSource
              drparg_u8TriggeringSource14: accessed-variable=prrAlgo10_Flags.u8TriggeringSource
              drparg_u8TriggeringSource15: accessed-variable=prrAlgo11_Flags.u8TriggeringSource
              drparg_u8TriggeringSource16: accessed-variable=prrAlgo12_Flags.u8TriggeringSource
              drparg_u8TriggeringSource17: accessed-variable=prrAlgo13_Flags.u8TriggeringSource
              drparg_u8TriggeringSource18: accessed-variable=prrAlgo16_Flags.u8TriggeringSource
              drparg_u8TriggeringSource19: accessed-variable=prrAlgo18_Flags.u8TriggeringSource
              drparg_u8TriggeringSource2: accessed-variable=prrAlgo14_Flags.u8TriggeringSource
              drparg_u8TriggeringSource20: accessed-variable=prrAlgo19_Flags.u8TriggeringSource
              drparg_u8TriggeringSource21: accessed-variable=prrAlgo20_Flags.u8TriggeringSource
              drparg_u8TriggeringSource22: accessed-variable=prrAlgo21_Flags.u8TriggeringSource
              drparg_u8TriggeringSource23: accessed-variable=prrAlgo22_Flags.u8TriggeringSource
              drparg_u8TriggeringSource24: accessed-variable=prrAlgo23_Flags.u8TriggeringSource
              drparg_u8TriggeringSource25: accessed-variable=prrAlgo24_Flags.u8TriggeringSource
              drparg_u8TriggeringSource26: accessed-variable=prrAlgo25_Flags.u8TriggeringSource
              drparg_u8TriggeringSource27: accessed-variable=prrAlgo26_Flags.u8TriggeringSource
              drparg_u8TriggeringSource28: accessed-variable=prrAlgo30_Flags.u8TriggeringSource
              drparg_u8TriggeringSource29: accessed-variable=prrAlgo31_Flags.u8TriggeringSource
              drparg_u8TriggeringSource3: accessed-variable=prrAlgo15_Flags.u8TriggeringSource
              drparg_u8TriggeringSource30: accessed-variable=prrAlgo32_Flags.u8TriggeringSource
              drparg_u8TriggeringSource31: accessed-variable=prrAlgo33_Flags.u8TriggeringSource
              drparg_u8TriggeringSource32: accessed-variable=prrAlgo34_Flags.u8TriggeringSource
              drparg_u8TriggeringSource33: accessed-variable=prrAlgo35_Flags.u8TriggeringSource
              drparg_u8TriggeringSource34: accessed-variable=prrAlgo36_Flags.u8TriggeringSource
              drparg_u8TriggeringSource35: accessed-variable=prrAlgo37_Flags.u8TriggeringSource
              drparg_u8TriggeringSource36: accessed-variable=prrAlgo38_Flags.u8TriggeringSource
              drparg_u8TriggeringSource4: accessed-variable=prrAlgo17_Flags.u8TriggeringSource
              drparg_u8TriggeringSource5: accessed-variable=prrAlgo01_Flags.u8TriggeringSource
              drparg_u8TriggeringSource6: accessed-variable=prrAlgo02_Flags.u8TriggeringSource
              drparg_u8TriggeringSource7: accessed-variable=prrAlgo03_Flags.u8TriggeringSource
              drparg_u8TriggeringSource8: accessed-variable=prrAlgo04_Flags.u8TriggeringSource
              drparg_u8TriggeringSource9: accessed-variable=prrAlgo05_Flags.u8TriggeringSource
              REC_prrSelectedCycle_u8CycleNumber: accessed-variable=prrSelectedCycle.u8CycleNumber
              REC_prrPresafeDisplay_b8TriggerPreSafeRequestStatus: accessed-variable=prrPresafeDisplay.b8TriggerPreSafeRequestStatus
          data-send-points:
            13 x access:
              SEND_IF_BltSlckDec_Md_XX_Stat_ST3_BltSlckDec_Md_XX_Stat_ST3: accessed-variable=IF_BltSlckDec_Md_XX_Stat_ST3.BltSlckDec_Md_XX_Stat_ST3
              SEND_IF_PS_Curve_FL_Stat_ST3_PS_Curve_FL_Stat_ST3: accessed-variable=IF_PS_Curve_FL_Stat_ST3.PS_Curve_FL_Stat_ST3
              SEND_IF_RBTM_FL_Disp_Rq_ST3_RBTM_FL_Disp_Rq_ST3: accessed-variable=IF_RBTM_FL_Disp_Rq_ST3.RBTM_FL_Disp_Rq_ST3
              SEND_IF_RBTM_FL_Tgl_ST3_RBTM_FL_Tgl_ST3: accessed-variable=IF_RBTM_FL_Tgl_ST3.RBTM_FL_Tgl_ST3
              SEND_P_PS_Curve_FR_Stat_ST3_PS_Curve_FR_Stat_ST3: accessed-variable=P_PS_Curve_FR_Stat_ST3.PS_Curve_FR_Stat_ST3
              SEND_P_RBTM_FR_Disp_Rq_ST3_RBTM_FR_Disp_Rq_ST3: accessed-variable=P_RBTM_FR_Disp_Rq_ST3.RBTM_FR_Disp_Rq_ST3
              SEND_P_RBTM_FR_Tgl_ST3_RBTM_FR_Tgl_ST3: accessed-variable=P_RBTM_FR_Tgl_ST3.RBTM_FR_Tgl_ST3
              SEND_RBTMFL_Actv_Lvl_ST35_RBTMFL_Actv_Lvl_ST35: accessed-variable=RBTMFL_Actv_Lvl_ST35.RBTMFL_Actv_Lvl_ST35
              SEND_RBTMFR_Actv_Lvl_ST35_RBTMFR_Actv_Lvl_ST35: accessed-variable=RBTMFR_Actv_Lvl_ST35.RBTMFR_Actv_Lvl_ST35
              SEND_P_RBTMFL_SP_ActvClient_ST35_RBTMFL_SP_ActvClient_ST35: accessed-variable=P_RBTMFL_SP_ActvClient_ST35.RBTMFL_SP_ActvClient_ST35
              SEND_P_RBTMFL_SP_FctPrecond_Stat_ST35_RBTMFL_SP_FctPrecond_Stat_ST35: accessed-variable=P_RBTMFL_SP_FctPrecond_Stat_ST35.RBTMFL_SP_FctPrecond_Stat_ST35
              SEND_P_RBTMFR_SP_ActvClient_ST35_RBTMFR_SP_ActvClient_ST35: accessed-variable=P_RBTMFR_SP_ActvClient_ST35.RBTMFR_SP_ActvClient_ST35
              SEND_P_RBTMFR_SP_FctPrecond_Stat_ST35_RBTMFR_SP_FctPrecond_Stat_ST35: accessed-variable=P_RBTMFR_SP_FctPrecond_Stat_ST35.RBTMFR_SP_FctPrecond_Stat_ST35
          read-local-variables:
            4 x access:
              Read_u8ResponseSignal: accessed-variable=u8ActvLvlSignal
              Read_u8FctPrecond_ProfileNotImplemented: accessed-variable=u8FctPrecond_ProfileNotImplemented
              Read_b8BuckleStatus: accessed-variable=u8BuckleStatus
              Read_u8RequestSource: accessed-variable=u8RequestSource
          10 x sync call:
            SSCP_pclModeManagement_CheckModeStatus: operation=pclModeManagement.CheckModeStatus
            SSCP_pclPyroDevice_GetPyroActivationStatus: operation=pclPyroDevice.GetPyroActivationStatus
            scp_AutotestCallback: operation=pclAutoTestCheckPowerUV.AutotestCallback
            scp_GetFromMinPos_mm: operation=pclBelt_D.GetFromMinPos_mm
            scp_GetFromT0_mm: operation=pclBelt_D.GetFromT0_mm
            scp_GetRange_mm: operation=pclBelt_D.GetRange_mm
            scp_GetSpeed_deg_s: operation=pclBelt_S.GetSpeed_deg_s
            scp_Get_A: operation=pclMotor_I.Get_A
            SC_pclAecStatus_GetAecGroupsStatus: operation=pclAecStatus.GetAecGroupsStatus
            SC_pclDiagRequestCycle_GetDiagRequestCycle: operation=pclDiagRequestCycle.GetDiagRequestCycle
        CIL_runCANToAppli
          data-receive-point-by-arguments:
            133 x access:
              drparg_b8InterruptFlag: accessed-variable=prrAlgo01_Flags.b8InterruptFlag
              drparg_b8InterruptFlag1: accessed-variable=prrAlgo02_Flags.b8InterruptFlag
              drparg_b8InterruptFlag12: accessed-variable=prrAlgo14_Flags.b8InterruptFlag
              drparg_b8InterruptFlag13: accessed-variable=prrAlgo15_Flags.b8InterruptFlag
              drparg_b8InterruptFlag14: accessed-variable=prrAlgo10_Flags.b8InterruptFlag
              drparg_b8InterruptFlag15: accessed-variable=prrAlgo11_Flags.b8InterruptFlag
              drparg_b8InterruptFlag16: accessed-variable=prrAlgo12_Flags.b8InterruptFlag
              drparg_b8InterruptFlag17: accessed-variable=prrAlgo13_Flags.b8InterruptFlag
              drparg_b8InterruptFlag18: accessed-variable=prrAlgo22_Flags.b8InterruptFlag
              drparg_b8InterruptFlag19: accessed-variable=prrAlgo23_Flags.b8InterruptFlag
              drparg_b8InterruptFlag2: accessed-variable=prrAlgo03_Flags.b8InterruptFlag
              drparg_b8InterruptFlag20: accessed-variable=prrAlgo24_Flags.b8InterruptFlag
              drparg_b8InterruptFlag21: accessed-variable=prrAlgo25_Flags.b8InterruptFlag
              drparg_b8InterruptFlag22: accessed-variable=prrAlgo26_Flags.b8InterruptFlag
              drparg_b8InterruptFlag23: accessed-variable=prrAlgo30_Flags.b8InterruptFlag
              drparg_b8InterruptFlag24: accessed-variable=prrAlgo31_Flags.b8InterruptFlag
              drparg_b8InterruptFlag25: accessed-variable=prrAlgo32_Flags.b8InterruptFlag
              drparg_b8InterruptFlag26: accessed-variable=prrAlgo33_Flags.b8InterruptFlag
              drparg_b8InterruptFlag27: accessed-variable=prrAlgo34_Flags.b8InterruptFlag
              drparg_b8InterruptFlag28: accessed-variable=prrAlgo35_Flags.b8InterruptFlag
              drparg_b8InterruptFlag29: accessed-variable=prrAlgo36_Flags.b8InterruptFlag
              drparg_b8InterruptFlag3: accessed-variable=prrAlgo04_Flags.b8InterruptFlag
              drparg_b8InterruptFlag30: accessed-variable=prrAlgo37_Flags.b8InterruptFlag
              drparg_b8InterruptFlag31: accessed-variable=prrAlgo38_Flags.b8InterruptFlag
              drparg_b8InterruptFlag4: accessed-variable=prrAlgo05_Flags.b8InterruptFlag
              drparg_b8InterruptFlag5: accessed-variable=prrAlgo06_Flags.b8InterruptFlag
              drparg_b8InterruptFlag6: accessed-variable=prrAlgo07_Flags.b8InterruptFlag
              drparg_b8InterruptFlag7: accessed-variable=prrAlgo08_Flags.b8InterruptFlag
              drparg_b8InterruptFlag8: accessed-variable=prrAlgo09_Flags.b8InterruptFlag
              drparg_b8PreActivationFlag: accessed-variable=prrAlgo01_Flags.b8PreActivationFlag
              drparg_b8PreActivationFlag1: accessed-variable=prrAlgo02_Flags.b8PreActivationFlag
              drparg_b8PreActivationFlag12: accessed-variable=prrAlgo14_Flags.b8PreActivationFlag
              drparg_b8PreActivationFlag13: accessed-variable=prrAlgo15_Flags.b8PreActivationFlag
              drparg_b8PreActivationFlag14: accessed-variable=prrAlgo10_Flags.b8PreActivationFlag
              drparg_b8PreActivationFlag15: accessed-variable=prrAlgo11_Flags.b8PreActivationFlag
              drparg_b8PreActivationFlag16: accessed-variable=prrAlgo12_Flags.b8PreActivationFlag
              drparg_b8PreActivationFlag17: accessed-variable=prrAlgo13_Flags.b8PreActivationFlag
              drparg_b8PreActivationFlag18: accessed-variable=prrAlgo22_Flags.b8PreActivationFlag
              drparg_b8PreActivationFlag19: accessed-variable=prrAlgo23_Flags.b8PreActivationFlag
              drparg_b8PreActivationFlag2: accessed-variable=prrAlgo03_Flags.b8PreActivationFlag
              drparg_b8PreActivationFlag20: accessed-variable=prrAlgo24_Flags.b8PreActivationFlag
              drparg_b8PreActivationFlag21: accessed-variable=prrAlgo25_Flags.b8PreActivationFlag
              drparg_b8PreActivationFlag22: accessed-variable=prrAlgo26_Flags.b8PreActivationFlag
              drparg_b8PreActivationFlag23: accessed-variable=prrAlgo30_Flags.b8PreActivationFlag
              drparg_b8PreActivationFlag24: accessed-variable=prrAlgo31_Flags.b8PreActivationFlag
              drparg_b8PreActivationFlag25: accessed-variable=prrAlgo32_Flags.b8PreActivationFlag
              drparg_b8PreActivationFlag26: accessed-variable=prrAlgo33_Flags.b8PreActivationFlag
              drparg_b8PreActivationFlag27: accessed-variable=prrAlgo34_Flags.b8PreActivationFlag
              drparg_b8PreActivationFlag28: accessed-variable=prrAlgo35_Flags.b8PreActivationFlag
              drparg_b8PreActivationFlag29: accessed-variable=prrAlgo36_Flags.b8PreActivationFlag
              drparg_b8PreActivationFlag3: accessed-variable=prrAlgo04_Flags.b8PreActivationFlag
              drparg_b8PreActivationFlag30: accessed-variable=prrAlgo37_Flags.b8PreActivationFlag
              drparg_b8PreActivationFlag31: accessed-variable=prrAlgo38_Flags.b8PreActivationFlag
              drparg_b8PreActivationFlag4: accessed-variable=prrAlgo05_Flags.b8PreActivationFlag
              drparg_b8PreActivationFlag5: accessed-variable=prrAlgo06_Flags.b8PreActivationFlag
              drparg_b8PreActivationFlag6: accessed-variable=prrAlgo07_Flags.b8PreActivationFlag
              drparg_b8PreActivationFlag7: accessed-variable=prrAlgo08_Flags.b8PreActivationFlag
              drparg_b8PreActivationFlag8: accessed-variable=prrAlgo09_Flags.b8PreActivationFlag
              drparg_b8TriggerFlag: accessed-variable=prrAlgo01_Flags.b8TriggerFlag
              drparg_b8TriggerFlag1: accessed-variable=prrAlgo02_Flags.b8TriggerFlag
              drparg_b8TriggerFlag12: accessed-variable=prrAlgo14_Flags.b8TriggerFlag
              drparg_b8TriggerFlag13: accessed-variable=prrAlgo15_Flags.b8TriggerFlag
              drparg_b8TriggerFlag14: accessed-variable=prrAlgo10_Flags.b8TriggerFlag
              drparg_b8TriggerFlag15: accessed-variable=prrAlgo11_Flags.b8TriggerFlag
              drparg_b8TriggerFlag16: accessed-variable=prrAlgo12_Flags.b8TriggerFlag
              drparg_b8TriggerFlag17: accessed-variable=prrAlgo13_Flags.b8TriggerFlag
              drparg_b8TriggerFlag18: accessed-variable=prrAlgo22_Flags.b8TriggerFlag
              drparg_b8TriggerFlag19: accessed-variable=prrAlgo23_Flags.b8TriggerFlag
              drparg_b8TriggerFlag2: accessed-variable=prrAlgo03_Flags.b8TriggerFlag
              drparg_b8TriggerFlag20: accessed-variable=prrAlgo24_Flags.b8TriggerFlag
              drparg_b8TriggerFlag21: accessed-variable=prrAlgo25_Flags.b8TriggerFlag
              drparg_b8TriggerFlag22: accessed-variable=prrAlgo26_Flags.b8TriggerFlag
              drparg_b8TriggerFlag23: accessed-variable=prrAlgo30_Flags.b8TriggerFlag
              drparg_b8TriggerFlag24: accessed-variable=prrAlgo31_Flags.b8TriggerFlag
              drparg_b8TriggerFlag25: accessed-variable=prrAlgo32_Flags.b8TriggerFlag
              drparg_b8TriggerFlag26: accessed-variable=prrAlgo33_Flags.b8TriggerFlag
              drparg_b8TriggerFlag27: accessed-variable=prrAlgo34_Flags.b8TriggerFlag
              drparg_b8TriggerFlag28: accessed-variable=prrAlgo35_Flags.b8TriggerFlag
              drparg_b8TriggerFlag29: accessed-variable=prrAlgo36_Flags.b8TriggerFlag
              drparg_b8TriggerFlag3: accessed-variable=prrAlgo04_Flags.b8TriggerFlag
              drparg_b8TriggerFlag30: accessed-variable=prrAlgo37_Flags.b8TriggerFlag
              drparg_b8TriggerFlag31: accessed-variable=prrAlgo38_Flags.b8TriggerFlag
              drparg_b8TriggerFlag4: accessed-variable=prrAlgo05_Flags.b8TriggerFlag
              drparg_b8TriggerFlag5: accessed-variable=prrAlgo06_Flags.b8TriggerFlag
              drparg_b8TriggerFlag6: accessed-variable=prrAlgo07_Flags.b8TriggerFlag
              drparg_b8TriggerFlag7: accessed-variable=prrAlgo08_Flags.b8TriggerFlag
              drparg_b8TriggerFlag8: accessed-variable=prrAlgo09_Flags.b8TriggerFlag
              REC_IG_Ign_Stat_Pr5_ST3_Ign_Stat_Pr5_ST3: accessed-variable=IG_Ign_Stat_Pr5_ST3.Ign_Stat_Pr5_ST3
              REC_IG_PresfAct_Adj_Pr5_ST3_PresfAct_Adj_Pr5_ST3: accessed-variable=IG_PresfAct_Adj_Pr5_ST3.PresfAct_Adj_Pr5_ST3
              REC_IG_ORC_Impact2_Pr5_ST3_ORC_Impact2_Pr5_ST3: accessed-variable=IG_ORC_Impact2_Pr5_ST3.ORC_Impact2_Pr5_ST3
              REC_IG_ORC_Impact3_Pr5_ST3_ORC_Impact3_Pr5_ST3: accessed-variable=IG_ORC_Impact3_Pr5_ST3.ORC_Impact3_Pr5_ST3
              REC_prrEnableCycle0_Element: accessed-variable=prrEnableCycle0.b8CycleValidity
              REC_prrEnableCycle1_Element: accessed-variable=prrEnableCycle1.b8CycleValidity
              REC_prrEnableCycle2_b8CycleValidity: accessed-variable=prrEnableCycle2.b8CycleValidity
              REC_prrEnableCycle3_b8CycleValidity: accessed-variable=prrEnableCycle3.b8CycleValidity
              REC_R_SBeltTens_SP_Lvl_Pr5_ST3_SBeltTens_SP_Lvl_Pr5_ST3: accessed-variable=R_SBeltTens_SP_Lvl_Pr5_ST3.SBeltTens_SP_Lvl_Pr5_ST3
              REC_R_PS_Curve_FL_Rq_HU_ST3_PS_Curve_FL_Rq_HU_ST3: accessed-variable=R_PS_Curve_FL_Rq_HU_ST3.PS_Curve_FL_Rq_HU_ST3
              REC_R_PS_Curve_FR_Rq_HU_ST3_PS_Curve_FR_Rq_HU_ST3: accessed-variable=R_PS_Curve_FR_Rq_HU_ST3.PS_Curve_FR_Rq_HU_ST3
              REC_R_Bckl_Sw_Fx_Stat_Pr5_ST3_Bckl_Sw_Fx_Stat_Pr5_ST3: accessed-variable=R_Bckl_Sw_Fx_Stat_Pr5_ST3.Bckl_Sw_Fx_Stat_Pr5_ST3
              REC_prrEnableCycle14_b8CycleValidity: accessed-variable=prrEnableCycle14.b8CycleValidity
              REC_prrEnableCycle18_b8CycleValidity: accessed-variable=prrEnableCycle18.b8CycleValidity
              REC_prrEnableCycle19_b8CycleValidity: accessed-variable=prrEnableCycle19.b8CycleValidity
              REC_prrEnableCycle{10..13}_b8CycleValidity: accessed-variable=prrEnableCycle{10..13}.b8CycleValidity
              REC_prrEnableCycle{15..17}_b8CycleValidity: accessed-variable=prrEnableCycle{15..17}.b8CycleValidity
              REC_prrEnableCycle{4..9}_b8CycleValidity: accessed-variable=prrEnableCycle{4..9}.b8CycleValidity
              REC_R_EVC_CfgList_01_08_Pr5_ST3_EVC_CfgList_01_08_Pr5_ST3: accessed-variable=R_EVC_CfgList_01_08_Pr5_ST3.EVC_CfgList_01_08_Pr5_ST3
              REC_R_PT4_PTCoor4_Pr5_ST3_PT4_PTCoor4_Pr5_ST3: accessed-variable=R_PT4_PTCoor4_Pr5_ST3.PT4_PTCoor4_Pr5_ST3
              REC_R_PT4_PTCoor_DrvPosn_Gear_Pr5_ST3_PT4_PTCoor_DrvPosn_Gear_Pr5_ST3: accessed-variable=R_PT4_PTCoor_DrvPosn_Gear_Pr5_ST3.PT4_PTCoor_DrvPosn_Gear_Pr5_ST3
              REC_R_BeltHdOvr_XX_Stat_ST3_BeltHdOvr_XX_Stat_ST3: accessed-variable=R_BeltHdOvr_XX_Stat_ST3.BeltHdOvr_XX_Stat_ST3
              REC_R_BltSlckDec_Md_Rq_HU_ST3_BltSlckDec_Md_Rq_HU_ST3: accessed-variable=R_BltSlckDec_Md_Rq_HU_ST3.BltSlckDec_Md_Rq_HU_ST3
              REC_prrEnableCycle{20..28}_b8CycleValidity: accessed-variable=prrEnableCycle{20..28}.b8CycleValidity
              REC_R_PN14_ProdMd_Stat_ST3_PN14_ProdMd_Stat_ST3: accessed-variable=R_PN14_ProdMd_Stat_ST3.PN14_ProdMd_Stat_ST3
              REC_R_PN14_TransMd_Stat_ST3_PN14_TransMd_Stat_ST3: accessed-variable=R_PN14_TransMd_Stat_ST3.PN14_TransMd_Stat_ST3
              REC_prrVehicleEquipmentValidity_u8VehicleEquipValidity: accessed-variable=prrVehicleEquipmentValidity.u8VehicleEquipValidity
              REC_prrVehicleEquipmentValidity_u8CodingValidity: accessed-variable=prrVehicleEquipmentValidity.u8CodingValidity
          data-send-points:
            30 x access:
              DSP_psrCustomerSpecific_b8IsCarCrankingActive: accessed-variable=psrCustomerSpecific.b8IsCarCrankingActive
              DSP_psrCustomerSpecific_b8IsCarCrashDetected: accessed-variable=psrCustomerSpecific.b8IsCarCrashDetected
              DSP_psrCustomerSpecific_b8PreCrashRequestEnable: accessed-variable=psrCustomerSpecific.b8PreCrashRequestEnable
              DSP_psrCustomerSpecific_u8BeltSlackStatus: accessed-variable=psrCustomerSpecific.u8BeltSlackStatus
              DSP_psrCustomerSpecific_u8HapticRequest: accessed-variable=psrCustomerSpecific.u8HapticRequest
              DSP_psrCustomerSpecific_u8PreCrashRequest: accessed-variable=psrCustomerSpecific.u8PreCrashRequest
              DSP_psrDriverControls_b8VehicleMovingBackwards: accessed-variable=psrDriverControls.b8VehicleMovingBackwards
              DSP_psrDriverControls_s16AccelerationPedalPositionRate: accessed-variable=psrDriverControls.s16AccelerationPedalPositionRate
              DSP_psrDriverControls_s16BrakePressureRate: accessed-variable=psrDriverControls.s16BrakePressureRate
              DSP_psrDriverControls_s16HWAngle: accessed-variable=psrDriverControls.s16HWAngle
              DSP_psrDriverControls_s16HWRate: accessed-variable=psrDriverControls.s16HWRate
              DSP_psrDriverControls_u16BrakePressure: accessed-variable=psrDriverControls.u16BrakePressure
              DSP_psrDriverControls_u16VehicleSpeed: accessed-variable=psrDriverControls.u16VehicleSpeed
              DSP_psrDriverControls_u8AccelerationPedalPosition: accessed-variable=psrDriverControls.u8AccelerationPedalPosition
              dsp_b8HardReleaseRequest: accessed-variable=psrCustomerSpecific.b8HardReleaseRequest
              SEND_psrCarAcceleration_b8IsCarAccelerationLow: accessed-variable=psrCarAcceleration.b8IsCarAccelerationLow
              SEND_psrCustomerSpecific_b8IsTrigOffEventAllowed: accessed-variable=psrCustomerSpecific.b8IsTrigOffEventAllowed
              SEND_prrCrashSeverityLevel_u8PreCrashSeverityLevel: accessed-variable=prrCrashSeverityLevel.u8PreCrashSeverityLevel
              SEND_psrBuckleDoorSwitch_u8BuckleSwitch: accessed-variable=psrBuckleDoorSwitch.u8BuckleSwitch
              SEND_psrBuckleDoorSwitch_u8DoorSwitch: accessed-variable=psrBuckleDoorSwitch.u8DoorSwitch
              SEND_psrCustomerSpecific_u8TriggerRequest: accessed-variable=psrCustomerSpecific.u8TriggerRequest
              SEND_psrPreSafeLvl_u8PreSafeLvl: accessed-variable=psrPreSafeLvl.u8PreSafeLvl
              SEND_psrCANInputBlockStatus_b8NVMBlockStatus: accessed-variable=psrCANInputBlockStatus.b8NVMBlockStatus
              SEND_psrCustomerSpecific_b8SignalRelInhibition: accessed-variable=psrCustomerSpecific.b8SignalRelInhibition
              SEND_isrIgnitionStatus_b8TriggerIgnitionStatus: accessed-variable=psrIgnitionStatus.b8TriggerIgnitionStatus
              SEND_psrProdModeStatus_b8TriggerProdModeStatus: accessed-variable=psrProdModeStatus.b8TriggerProdModeStatus
              SEND_psrTransportationModeStatus_b8TransportationModeStatus: accessed-variable=psrTransportationModeStatus.b8TransportationModeStatus
              SEND_psrEngStartStatus_b8EngStartStatus: accessed-variable=psrEngStartStatus.b8EngStartStatus
              SEND_psrIgnitionStatus_b8TriggerIgnitionStatusEnableStorageCondition: accessed-variable=psrIgnitionStatus.b8TriggerIgnitionStatusEnableStorageCondition
              SEND_psrExtTestPres_b8ExtTesterPresent: accessed-variable=psrExtTestPres.b8ExtTesterPresent
          sync call SC_pclAecStatus_GetAecStatus: operation=pclAecStatus.GetAecStatus
          written-local-variables:
            6 x access:
              WRITE_b8BeltSlackStatus: accessed-variable=u8BuckleStatus
              WRITE_b8CarCrashDetected: accessed-variable=b8CarCrashDetected
              WRITE_b8PreCrashRequestEnable: accessed-variable=b8PreCrashRequestEnable
              WRITE_u8ResponseSignal: accessed-variable=u8ActvLvlSignal
              WRITE_u8FctPrecond_ProfileNotImplemented: accessed-variable=u8FctPrecond_ProfileNotImplemented
              WRITE_u8RequestSource: accessed-variable=u8RequestSource
        CIL_runManageMeasurementFrame
          data-receive-point-by-arguments:
            access REC_prrCycleNumber_u8CycleNumber: accessed-variable=prrCycleNumber.u8CycleNumber
            access REC_prrStepNumber_u8StepNumber: accessed-variable=prrStepNumber.u8StepNumber
            access REC_prrSelectedCycle_u8CycleNumber: accessed-variable=prrSelectedCycle.u8CycleNumber
          data-send-points:
            access SEND_P_Meas_RBTM_FL_ST3_Meas8_RBTM_FL_ST3: accessed-variable=P_Meas_RBTM_FL_ST3.Meas8_RBTM_FL_ST3
            access SEND_P_Meas_RBTM_FR_ST3_Meas8_RBTM_FR_ST3: accessed-variable=P_Meas_RBTM_FR_ST3.Meas8_RBTM_FR_ST3
          42 x sync call:
            SC_pclMotor_T_GetDeficiencyLevel: operation=pclMotor_T.GetDeficiencyLevel
            SC_pclECU_T_GetFiltered: operation=pclECU_T.GetFiltered
            SC_pclECU_T_GetFiltered_deg: operation=pclECU_T.GetFiltered_deg
            SC_pclGND_V_Get: operation=pclGND_V.Get
            SC_pclGND_V_Get_100ms: operation=pclGND_V.Get_100ms
            SC_pclGND_V_Get_20ms: operation=pclGND_V.Get_20ms
            SC_pclHS1_V_Get: operation=pclHS1_V.Get
            SC_pclKL30_V_Get: operation=pclKL30_V.Get
            SC_pclKL30_V_Get_100ms: operation=pclKL30_V.Get_100ms
            SC_pclKL30_V_Get_10ms: operation=pclKL30_V.Get_10ms
            SC_pclKL30_V_Get_20ms: operation=pclKL30_V.Get_20ms
            SC_pclKL30_V_Get_2ms: operation=pclKL30_V.Get_2ms
            SC_pclMotor_I_Get_A: operation=pclMotor_I.Get_A
            SC_pclMotor_I_Get_mA: operation=pclMotor_I.Get_mA
            SC_pclMotor_P_GetPowerOrder: operation=pclMotor_P.GetPowerOrder
            SC_pclMotor_Vn_Get: operation=pclMotor_Vn.Get
            SC_pclMotor_Vn_Get_100ms: operation=pclMotor_Vn.Get_100ms
            SC_pclMotor_Vn_Get_20ms: operation=pclMotor_Vn.Get_20ms
            SC_pclMotor_Vp_Get: operation=pclMotor_Vp.Get
            SC_pclMotor_Vp_Get_100ms: operation=pclMotor_Vp.Get_100ms
            SC_pclMotor_Vp_Get_20ms: operation=pclMotor_Vp.Get_20ms
            SC_pclREFCpuReg_V_Get: operation=pclREFCpuReg_V.Get
            SC_pclREFHigh_V_Get: operation=pclREFHigh_V.Get
            SC_pclREFLow_V_raw_Get: operation=pclREFLow_V_raw.Get
            SC_pclREFMid_V_Get: operation=pclREFMid_V.Get
            SC_pclHBS_A_V_raw_Get_10ms: operation=pclHBS_A_V_raw.Get_10ms
            SC_pclHBS_B_V_raw_Get_10ms: operation=pclHBS_B_V_raw.Get_10ms
            SC_pclHS1_V_raw_Get_100ms: operation=pclHS1_V_raw.Get_100ms
            SC_pclHS1_V_raw_Get_10ms: operation=pclHS1_V_raw.Get_10ms
            SC_pclHS1_V_raw_Get_20ms: operation=pclHS1_V_raw.Get_20ms
            SC_pclREFLow_V_raw_Get_100ms: operation=pclREFLow_V_raw.Get_100ms
            SC_pclREFLow_V_raw_Get_10ms: operation=pclREFLow_V_raw.Get_10ms
            SC_pclMotor_In_raw_raw_Get_10ms: operation=pclMotor_In_raw.raw_Get_10ms
            SC_pclMotor_Ip_raw_raw_Get_10ms: operation=pclMotor_Ip_raw.raw_Get_10ms
            SC_pclAutotestServices_GetTestResult: operation=pclAutotestServices.GetTestResult
            SC_pclHBS_A_V_raw_Get: operation=pclHBS_A_V_raw.Get
            SC_pclHBS_B_V_raw_Get: operation=pclHBS_B_V_raw.Get
            SC_pclKL30_V_raw_Get: operation=pclKL30_V_raw.Get
            SC_pclHS1_V_raw_Get: operation=pclHS1_V_raw.Get
            SC_pclMotor_In_raw_raw_Get: operation=pclMotor_In_raw.raw_Get
            SC_pclMotor_Ip_raw_raw_Get: operation=pclMotor_Ip_raw.raw_Get
            SC_pclBelt_D_GetFromT0_deg: operation=pclBelt_D.GetFromT0_deg
        CIL_Autotest_Presafe_CheckTimeoutError: can-be-invoked-concurrently=true
        CIL_Autotest_Buckle_CheckTimeoutError: can-be-invoked-concurrently=true
        CIL_Autotest_CheckImplausibleData_Presafe: can-be-invoked-concurrently=true
        CIL_Autotest_CheckImplausibleData_Ignition: can-be-invoked-concurrently=true
        CIL_Autotest_CheckImplausibleData_Buckle: can-be-invoked-concurrently=true
        CIL_runGetInputSignalPresafeRecorderInfo
        CIL_Autotest_CheckTimeoutError_Ignition: can-be-invoked-concurrently=true
        CIL_Autotest_CheckTimeoutError_API: can-be-invoked-concurrently=true
        CIL_Autotest_CheckTimeoutError_BelthandoverR: can-be-invoked-concurrently=true
        CIL_Autotest_CheckTimeoutError_BelthandoverL: can-be-invoked-concurrently=true
        CIL_Autotest_CheckTimeoutError_Powertrain: can-be-invoked-concurrently=true
        CIL_Autotest_CheckImplausibleData_PowertrainDrv: can-be-invoked-concurrently=true
        CIL_Autotest_CheckImplausibleData_ORC: can-be-invoked-concurrently=true
        CIL_Autotest_CheckSteeringConfiguration: can-be-invoked-concurrently=true
        CIL_Autotest_CheckImplausibleData_PowertrainRdy: can-be-invoked-concurrently=true
        CIL_Autotest_CheckImplausibleData_API: can-be-invoked-concurrently=true
        CIL_Autotest_CheckVariantCoding: can-be-invoked-concurrently=true
        CIL_Autotest_CheckTimeoutError_OdoSpeedometer: can-be-invoked-concurrently=true
        CIL_Autotest_CheckTimeoutError_BeltAdj: can-be-invoked-concurrently=true
  swc implementation CIL_AC_CommunicationInteractionLayer_Implementation: behavior=CIL_IB_CommunicationInteractionLayer
